AUTOSAR XML (schema 00050)
package /IBNvBlkSWC_1
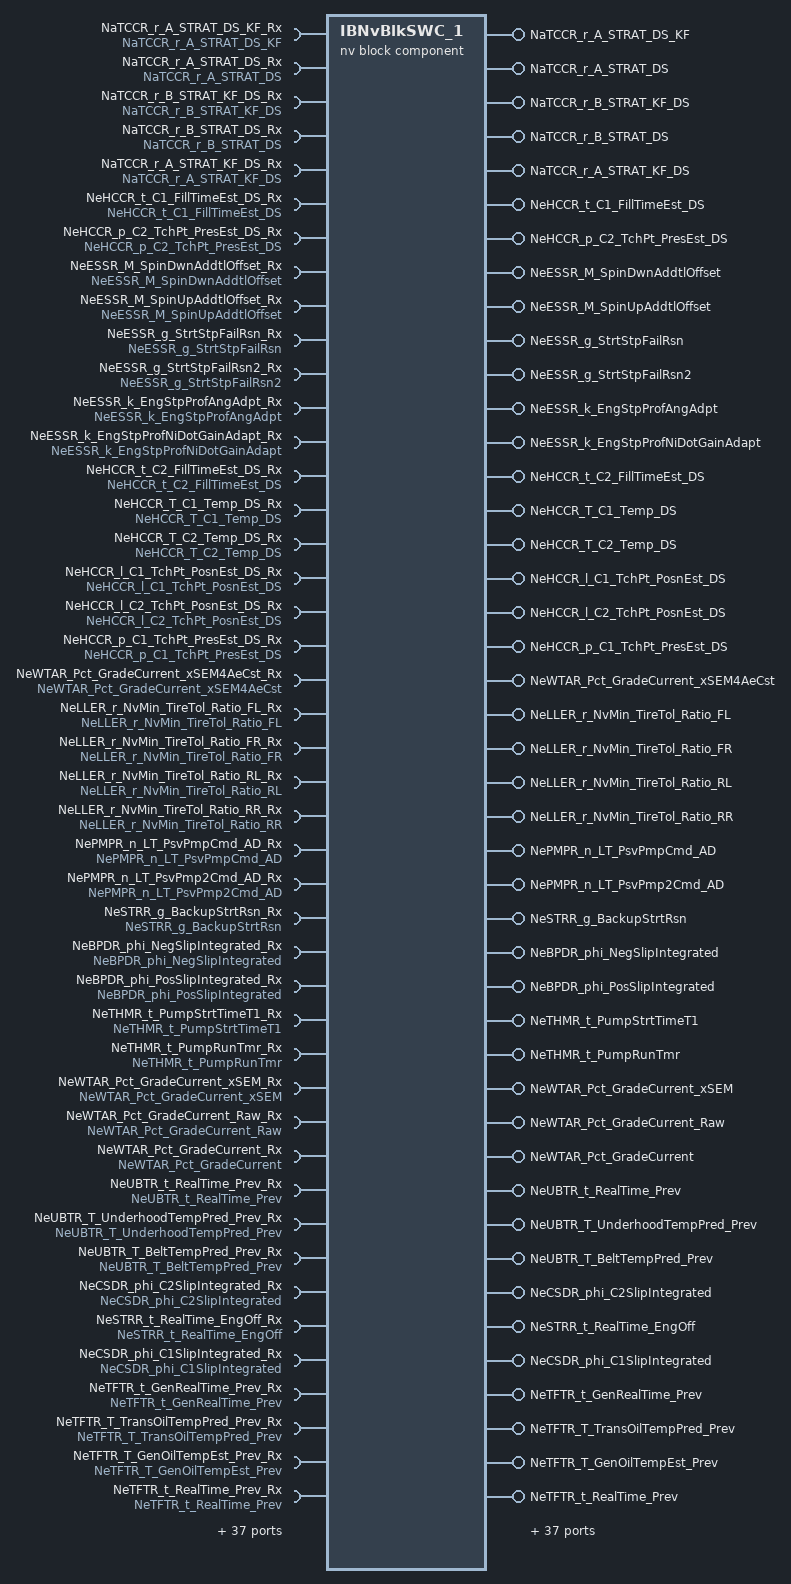
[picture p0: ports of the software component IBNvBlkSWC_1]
  nv block sw component type IBNvBlkSWC_1
    provide port NaTCCR_r_A_STRAT_DS_KF: nv-provide-com-spec{ram-block-init-value=ArrayValues:[ArrayElement0:0, ArrayElement1:0, ArrayElement2:0, ArrayElement3:0, ArrayElement4:0, ArrayElement5:0, ArrayElement6:0, ArrayElement7:0, ArrayElement8:0, ArrayElement9:0, ArrayElement10:0, ArrayElement11:0, ArrayElement12:0, ArrayElement13:0, ArrayElement14:0, ArrayElement15:0, ArrayElement16:0, ArrayElement17:0, ArrayElement18:0, ArrayElement19:0, ArrayElement20:0, ArrayElement21:0], rom-block-init-value=ArrayValues:[ArrayElement0:0, ArrayElement1:0, ArrayElement2:0, ArrayElement3:0, ArrayElement4:0, ArrayElement5:0, ArrayElement6:0, ArrayElement7:0, ArrayElement8:0, ArrayElement9:0, ArrayElement10:0, ArrayElement11:0, ArrayElement12:0, ArrayElement13:0, ArrayElement14:0, ArrayElement15:0, ArrayElement16:0, ArrayElement17:0, ArrayElement18:0, ArrayElement19:0, ArrayElement20:0, ArrayElement21:0], variable=NaTCCR_r_A_STRAT_DS_KF}, provided-interface=NaTCCR_r_A_STRAT_DS_KF
    require port NaTCCR_r_A_STRAT_DS_KF_Rx: nv-require-com-spec{init-value=ArrayValues:[ArrayElement0:0, ArrayElement1:0, ArrayElement2:0, ArrayElement3:0, ArrayElement4:0, ArrayElement5:0, ArrayElement6:0, ArrayElement7:0, ArrayElement8:0, ArrayElement9:0, ArrayElement10:0, ArrayElement11:0, ArrayElement12:0, ArrayElement13:0, ArrayElement14:0, ArrayElement15:0, ArrayElement16:0, ArrayElement17:0, ArrayElement18:0, ArrayElement19:0, ArrayElement20:0, ArrayElement21:0], variable=NaTCCR_r_A_STRAT_DS_KF}, required-interface=NaTCCR_r_A_STRAT_DS_KF
    provide port NaTCCR_r_A_STRAT_DS: nv-provide-com-spec{ram-block-init-value=ArrayValues:[ArrayElement0:0, ArrayElement1:0, ArrayElement2:0, ArrayElement3:0, ArrayElement4:0, ArrayElement5:0, ArrayElement6:0, ArrayElement7:0, ArrayElement8:0, ArrayElement9:0, ArrayElement10:0, ArrayElement11:0, ArrayElement12:0, ArrayElement13:0, ArrayElement14:0, ArrayElement15:0, ArrayElement16:0, ArrayElement17:0, ArrayElement18:0, ArrayElement19:0, ArrayElement20:0, ArrayElement21:0], rom-block-init-value=ArrayValues:[ArrayElement0:0, ArrayElement1:0, ArrayElement2:0, ArrayElement3:0, ArrayElement4:0, ArrayElement5:0, ArrayElement6:0, ArrayElement7:0, ArrayElement8:0, ArrayElement9:0, ArrayElement10:0, ArrayElement11:0, ArrayElement12:0, ArrayElement13:0, ArrayElement14:0, ArrayElement15:0, ArrayElement16:0, ArrayElement17:0, ArrayElement18:0, ArrayElement19:0, ArrayElement20:0, ArrayElement21:0], variable=NaTCCR_r_A_STRAT_DS}, provided-interface=NaTCCR_r_A_STRAT_DS
    require port NaTCCR_r_A_STRAT_DS_Rx: nv-require-com-spec{init-value=ArrayValues:[ArrayElement0:0, ArrayElement1:0, ArrayElement2:0, ArrayElement3:0, ArrayElement4:0, ArrayElement5:0, ArrayElement6:0, ArrayElement7:0, ArrayElement8:0, ArrayElement9:0, ArrayElement10:0, ArrayElement11:0, ArrayElement12:0, ArrayElement13:0, ArrayElement14:0, ArrayElement15:0, ArrayElement16:0, ArrayElement17:0, ArrayElement18:0, ArrayElement19:0, ArrayElement20:0, ArrayElement21:0], variable=NaTCCR_r_A_STRAT_DS}, required-interface=NaTCCR_r_A_STRAT_DS
    provide port NaTCCR_r_B_STRAT_KF_DS: nv-provide-com-spec{ram-block-init-value=ArrayValues:[ArrayElement0:0, ArrayElement1:0, ArrayElement2:0, ArrayElement3:0, ArrayElement4:0, ArrayElement5:0, ArrayElement6:0, ArrayElement7:0, ArrayElement8:0, ArrayElement9:0, ArrayElement10:0, ArrayElement11:0, ArrayElement12:0, ArrayElement13:0, ArrayElement14:0, ArrayElement15:0, ArrayElement16:0, ArrayElement17:0, ArrayElement18:0, ArrayElement19:0, ArrayElement20:0, ArrayElement21:0], rom-block-init-value=ArrayValues:[ArrayElement0:0, ArrayElement1:0, ArrayElement2:0, ArrayElement3:0, ArrayElement4:0, ArrayElement5:0, ArrayElement6:0, ArrayElement7:0, ArrayElement8:0, ArrayElement9:0, ArrayElement10:0, ArrayElement11:0, ArrayElement12:0, ArrayElement13:0, ArrayElement14:0, ArrayElement15:0, ArrayElement16:0, ArrayElement17:0, ArrayElement18:0, ArrayElement19:0, ArrayElement20:0, ArrayElement21:0], variable=NaTCCR_r_B_STRAT_KF_DS}, provided-interface=NaTCCR_r_B_STRAT_KF_DS
    require port NaTCCR_r_B_STRAT_KF_DS_Rx: nv-require-com-spec{init-value=ArrayValues:[ArrayElement0:0, ArrayElement1:0, ArrayElement2:0, ArrayElement3:0, ArrayElement4:0, ArrayElement5:0, ArrayElement6:0, ArrayElement7:0, ArrayElement8:0, ArrayElement9:0, ArrayElement10:0, ArrayElement11:0, ArrayElement12:0, ArrayElement13:0, ArrayElement14:0, ArrayElement15:0, ArrayElement16:0, ArrayElement17:0, ArrayElement18:0, ArrayElement19:0, ArrayElement20:0, ArrayElement21:0], variable=NaTCCR_r_B_STRAT_KF_DS}, required-interface=NaTCCR_r_B_STRAT_KF_DS
    provide port NaTCCR_r_B_STRAT_DS: nv-provide-com-spec{ram-block-init-value=ArrayValues:[ArrayElement0:0, ArrayElement1:0, ArrayElement2:0, ArrayElement3:0, ArrayElement4:0, ArrayElement5:0, ArrayElement6:0, ArrayElement7:0, ArrayElement8:0, ArrayElement9:0, ArrayElement10:0, ArrayElement11:0, ArrayElement12:0, ArrayElement13:0, ArrayElement14:0, ArrayElement15:0, ArrayElement16:0, ArrayElement17:0, ArrayElement18:0, ArrayElement19:0, ArrayElement20:0, ArrayElement21:0], rom-block-init-value=ArrayValues:[ArrayElement0:0, ArrayElement1:0, ArrayElement2:0, ArrayElement3:0, ArrayElement4:0, ArrayElement5:0, ArrayElement6:0, ArrayElement7:0, ArrayElement8:0, ArrayElement9:0, ArrayElement10:0, ArrayElement11:0, ArrayElement12:0, ArrayElement13:0, ArrayElement14:0, ArrayElement15:0, ArrayElement16:0, ArrayElement17:0, ArrayElement18:0, ArrayElement19:0, ArrayElement20:0, ArrayElement21:0], variable=NaTCCR_r_B_STRAT_DS}, provided-interface=NaTCCR_r_B_STRAT_DS
    require port NaTCCR_r_B_STRAT_DS_Rx: nv-require-com-spec{init-value=ArrayValues:[ArrayElement0:0, ArrayElement1:0, ArrayElement2:0, ArrayElement3:0, ArrayElement4:0, ArrayElement5:0, ArrayElement6:0, ArrayElement7:0, ArrayElement8:0, ArrayElement9:0, ArrayElement10:0, ArrayElement11:0, ArrayElement12:0, ArrayElement13:0, ArrayElement14:0, ArrayElement15:0, ArrayElement16:0, ArrayElement17:0, ArrayElement18:0, ArrayElement19:0, ArrayElement20:0, ArrayElement21:0], variable=NaTCCR_r_B_STRAT_DS}, required-interface=NaTCCR_r_B_STRAT_DS
    provide port NaTCCR_r_A_STRAT_KF_DS: nv-provide-com-spec{ram-block-init-value=ArrayValues:[ArrayElement0:0, ArrayElement1:0, ArrayElement2:0, ArrayElement3:0, ArrayElement4:0, ArrayElement5:0, ArrayElement6:0, ArrayElement7:0, ArrayElement8:0, ArrayElement9:0, ArrayElement10:0, ArrayElement11:0, ArrayElement12:0, ArrayElement13:0, ArrayElement14:0, ArrayElement15:0, ArrayElement16:0, ArrayElement17:0, ArrayElement18:0, ArrayElement19:0, ArrayElement20:0, ArrayElement21:0], rom-block-init-value=ArrayValues:[ArrayElement0:0, ArrayElement1:0, ArrayElement2:0, ArrayElement3:0, ArrayElement4:0, ArrayElement5:0, ArrayElement6:0, ArrayElement7:0, ArrayElement8:0, ArrayElement9:0, ArrayElement10:0, ArrayElement11:0, ArrayElement12:0, ArrayElement13:0, ArrayElement14:0, ArrayElement15:0, ArrayElement16:0, ArrayElement17:0, ArrayElement18:0, ArrayElement19:0, ArrayElement20:0, ArrayElement21:0], variable=NaTCCR_r_A_STRAT_KF_DS}, provided-interface=NaTCCR_r_A_STRAT_KF_DS
    require port NaTCCR_r_A_STRAT_KF_DS_Rx: nv-require-com-spec{init-value=ArrayValues:[ArrayElement0:0, ArrayElement1:0, ArrayElement2:0, ArrayElement3:0, ArrayElement4:0, ArrayElement5:0, ArrayElement6:0, ArrayElement7:0, ArrayElement8:0, ArrayElement9:0, ArrayElement10:0, ArrayElement11:0, ArrayElement12:0, ArrayElement13:0, ArrayElement14:0, ArrayElement15:0, ArrayElement16:0, ArrayElement17:0, ArrayElement18:0, ArrayElement19:0, ArrayElement20:0, ArrayElement21:0], variable=NaTCCR_r_A_STRAT_KF_DS}, required-interface=NaTCCR_r_A_STRAT_KF_DS
    provide port NeHCCR_t_C1_FillTimeEst_DS: nv-provide-com-spec{ram-block-init-value=Value:4294967295, rom-block-init-value=Value:4294967295, variable=NeHCCR_t_C1_FillTimeEst_DS}, provided-interface=NeHCCR_t_C1_FillTimeEst_DS
    require port NeHCCR_t_C1_FillTimeEst_DS_Rx: nv-require-com-spec{init-value=Value:4294967295, variable=NeHCCR_t_C1_FillTimeEst_DS}, required-interface=NeHCCR_t_C1_FillTimeEst_DS
    provide port NeHCCR_p_C2_TchPt_PresEst_DS: nv-provide-com-spec{ram-block-init-value=Value:4294967295, rom-block-init-value=Value:4294967295, variable=NeHCCR_p_C2_TchPt_PresEst_DS}, provided-interface=NeHCCR_p_C2_TchPt_PresEst_DS
    require port NeHCCR_p_C2_TchPt_PresEst_DS_Rx: nv-require-com-spec{init-value=Value:4294967295, variable=NeHCCR_p_C2_TchPt_PresEst_DS}, required-interface=NeHCCR_p_C2_TchPt_PresEst_DS
    provide port NeESSR_M_SpinDwnAddtlOffset: nv-provide-com-spec{ram-block-init-value=Value:0, rom-block-init-value=Value:0, variable=NeESSR_M_SpinDwnAddtlOffset}, provided-interface=NeESSR_M_SpinDwnAddtlOffset
    require port NeESSR_M_SpinDwnAddtlOffset_Rx: nv-require-com-spec{init-value=Value:0, variable=NeESSR_M_SpinDwnAddtlOffset}, required-interface=NeESSR_M_SpinDwnAddtlOffset
    provide port NeESSR_M_SpinUpAddtlOffset: nv-provide-com-spec{ram-block-init-value=Value:0, rom-block-init-value=Value:0, variable=NeESSR_M_SpinUpAddtlOffset}, provided-interface=NeESSR_M_SpinUpAddtlOffset
    require port NeESSR_M_SpinUpAddtlOffset_Rx: nv-require-com-spec{init-value=Value:0, variable=NeESSR_M_SpinUpAddtlOffset}, required-interface=NeESSR_M_SpinUpAddtlOffset
    provide port NeESSR_g_StrtStpFailRsn: nv-provide-com-spec{ram-block-init-value=Value:4294967295, rom-block-init-value=Value:4294967295, variable=NeESSR_g_StrtStpFailRsn}, provided-interface=NeESSR_g_StrtStpFailRsn
    require port NeESSR_g_StrtStpFailRsn_Rx: nv-require-com-spec{init-value=Value:4294967295, variable=NeESSR_g_StrtStpFailRsn}, required-interface=NeESSR_g_StrtStpFailRsn
    provide port NeESSR_g_StrtStpFailRsn2: nv-provide-com-spec{ram-block-init-value=Value:0, rom-block-init-value=Value:0, variable=NeESSR_g_StrtStpFailRsn2}, provided-interface=NeESSR_g_StrtStpFailRsn2
    require port NeESSR_g_StrtStpFailRsn2_Rx: nv-require-com-spec{init-value=Value:0, variable=NeESSR_g_StrtStpFailRsn2}, required-interface=NeESSR_g_StrtStpFailRsn2
    provide port NeESSR_k_EngStpProfAngAdpt: nv-provide-com-spec{ram-block-init-value=Value:0, rom-block-init-value=Value:0, variable=NeESSR_k_EngStpProfAngAdpt}, provided-interface=NeESSR_k_EngStpProfAngAdpt
    require port NeESSR_k_EngStpProfAngAdpt_Rx: nv-require-com-spec{init-value=Value:0, variable=NeESSR_k_EngStpProfAngAdpt}, required-interface=NeESSR_k_EngStpProfAngAdpt
    provide port NeESSR_k_EngStpProfNiDotGainAdapt: nv-provide-com-spec{ram-block-init-value=Value:0, rom-block-init-value=Value:0, variable=NeESSR_k_EngStpProfNiDotGainAdapt}, provided-interface=NeESSR_k_EngStpProfNiDotGainAdapt
    require port NeESSR_k_EngStpProfNiDotGainAdapt_Rx: nv-require-com-spec{init-value=Value:0, variable=NeESSR_k_EngStpProfNiDotGainAdapt}, required-interface=NeESSR_k_EngStpProfNiDotGainAdapt
    provide port NeHCCR_t_C2_FillTimeEst_DS: nv-provide-com-spec{ram-block-init-value=Value:4294967295, rom-block-init-value=Value:4294967295, variable=NeHCCR_t_C2_FillTimeEst_DS}, provided-interface=NeHCCR_t_C2_FillTimeEst_DS
    require port NeHCCR_t_C2_FillTimeEst_DS_Rx: nv-require-com-spec{init-value=Value:4294967295, variable=NeHCCR_t_C2_FillTimeEst_DS}, required-interface=NeHCCR_t_C2_FillTimeEst_DS
    provide port NeHCCR_T_C1_Temp_DS: nv-provide-com-spec{ram-block-init-value=Value:4294967295, rom-block-init-value=Value:4294967295, variable=NeHCCR_T_C1_Temp_DS}, provided-interface=NeHCCR_T_C1_Temp_DS
    require port NeHCCR_T_C1_Temp_DS_Rx: nv-require-com-spec{init-value=Value:4294967295, variable=NeHCCR_T_C1_Temp_DS}, required-interface=NeHCCR_T_C1_Temp_DS
    provide port NeHCCR_T_C2_Temp_DS: nv-provide-com-spec{ram-block-init-value=Value:4294967295, rom-block-init-value=Value:4294967295, variable=NeHCCR_T_C2_Temp_DS}, provided-interface=NeHCCR_T_C2_Temp_DS
    require port NeHCCR_T_C2_Temp_DS_Rx: nv-require-com-spec{init-value=Value:4294967295, variable=NeHCCR_T_C2_Temp_DS}, required-interface=NeHCCR_T_C2_Temp_DS
    provide port NeHCCR_l_C1_TchPt_PosnEst_DS: nv-provide-com-spec{ram-block-init-value=Value:4294967295, rom-block-init-value=Value:4294967295, variable=NeHCCR_l_C1_TchPt_PosnEst_DS}, provided-interface=NeHCCR_l_C1_TchPt_PosnEst_DS
    require port NeHCCR_l_C1_TchPt_PosnEst_DS_Rx: nv-require-com-spec{init-value=Value:4294967295, variable=NeHCCR_l_C1_TchPt_PosnEst_DS}, required-interface=NeHCCR_l_C1_TchPt_PosnEst_DS
    provide port NeHCCR_l_C2_TchPt_PosnEst_DS: nv-provide-com-spec{ram-block-init-value=Value:4294967295, rom-block-init-value=Value:4294967295, variable=NeHCCR_l_C2_TchPt_PosnEst_DS}, provided-interface=NeHCCR_l_C2_TchPt_PosnEst_DS
    require port NeHCCR_l_C2_TchPt_PosnEst_DS_Rx: nv-require-com-spec{init-value=Value:4294967295, variable=NeHCCR_l_C2_TchPt_PosnEst_DS}, required-interface=NeHCCR_l_C2_TchPt_PosnEst_DS
    provide port NeHCCR_p_C1_TchPt_PresEst_DS: nv-provide-com-spec{ram-block-init-value=Value:4294967295, rom-block-init-value=Value:4294967295, variable=NeHCCR_p_C1_TchPt_PresEst_DS}, provided-interface=NeHCCR_p_C1_TchPt_PresEst_DS
    require port NeHCCR_p_C1_TchPt_PresEst_DS_Rx: nv-require-com-spec{init-value=Value:4294967295, variable=NeHCCR_p_C1_TchPt_PresEst_DS}, required-interface=NeHCCR_p_C1_TchPt_PresEst_DS
    provide port NeWTAR_Pct_GradeCurrent_xSEM4AeCst: nv-provide-com-spec{ram-block-init-value=Value:0, rom-block-init-value=Value:0, variable=NeWTAR_Pct_GradeCurrent_xSEM4AeCst}, provided-interface=NeWTAR_Pct_GradeCurrent_xSEM4AeCst
    require port NeWTAR_Pct_GradeCurrent_xSEM4AeCst_Rx: nv-require-com-spec{init-value=Value:0, variable=NeWTAR_Pct_GradeCurrent_xSEM4AeCst}, required-interface=NeWTAR_Pct_GradeCurrent_xSEM4AeCst
    provide port NeLLER_r_NvMin_TireTol_Ratio_FL: nv-provide-com-spec{ram-block-init-value=Value:0, rom-block-init-value=Value:0, variable=NeLLER_r_NvMin_TireTol_Ratio_FL}, provided-interface=NeLLER_r_NvMin_TireTol_Ratio_FL
    require port NeLLER_r_NvMin_TireTol_Ratio_FL_Rx: nv-require-com-spec{init-value=Value:0, variable=NeLLER_r_NvMin_TireTol_Ratio_FL}, required-interface=NeLLER_r_NvMin_TireTol_Ratio_FL
    provide port NeLLER_r_NvMin_TireTol_Ratio_FR: nv-provide-com-spec{ram-block-init-value=Value:0, rom-block-init-value=Value:0, variable=NeLLER_r_NvMin_TireTol_Ratio_FR}, provided-interface=NeLLER_r_NvMin_TireTol_Ratio_FR
    require port NeLLER_r_NvMin_TireTol_Ratio_FR_Rx: nv-require-com-spec{init-value=Value:0, variable=NeLLER_r_NvMin_TireTol_Ratio_FR}, required-interface=NeLLER_r_NvMin_TireTol_Ratio_FR
    provide port NeLLER_r_NvMin_TireTol_Ratio_RL: nv-provide-com-spec{ram-block-init-value=Value:0, rom-block-init-value=Value:0, variable=NeLLER_r_NvMin_TireTol_Ratio_RL}, provided-interface=NeLLER_r_NvMin_TireTol_Ratio_RL
    require port NeLLER_r_NvMin_TireTol_Ratio_RL_Rx: nv-require-com-spec{init-value=Value:0, variable=NeLLER_r_NvMin_TireTol_Ratio_RL}, required-interface=NeLLER_r_NvMin_TireTol_Ratio_RL
    provide port NeLLER_r_NvMin_TireTol_Ratio_RR: nv-provide-com-spec{ram-block-init-value=Value:0, rom-block-init-value=Value:0, variable=NeLLER_r_NvMin_TireTol_Ratio_RR}, provided-interface=NeLLER_r_NvMin_TireTol_Ratio_RR
    require port NeLLER_r_NvMin_TireTol_Ratio_RR_Rx: nv-require-com-spec{init-value=Value:0, variable=NeLLER_r_NvMin_TireTol_Ratio_RR}, required-interface=NeLLER_r_NvMin_TireTol_Ratio_RR
    provide port NePMPR_n_LT_PsvPmpCmd_AD: nv-provide-com-spec{ram-block-init-value=Value:0, rom-block-init-value=Value:0, variable=NePMPR_n_LT_PsvPmpCmd_AD}, provided-interface=NePMPR_n_LT_PsvPmpCmd_AD
    require port NePMPR_n_LT_PsvPmpCmd_AD_Rx: nv-require-com-spec{init-value=Value:0, variable=NePMPR_n_LT_PsvPmpCmd_AD}, required-interface=NePMPR_n_LT_PsvPmpCmd_AD
    provide port NePMPR_n_LT_PsvPmp2Cmd_AD: nv-provide-com-spec{ram-block-init-value=Value:0, rom-block-init-value=Value:0, variable=NePMPR_n_LT_PsvPmp2Cmd_AD}, provided-interface=NePMPR_n_LT_PsvPmp2Cmd_AD
    require port NePMPR_n_LT_PsvPmp2Cmd_AD_Rx: nv-require-com-spec{init-value=Value:0, variable=NePMPR_n_LT_PsvPmp2Cmd_AD}, required-interface=NePMPR_n_LT_PsvPmp2Cmd_AD
    provide port NeSTRR_g_BackupStrtRsn: nv-provide-com-spec{ram-block-init-value=Value:0, rom-block-init-value=Value:0, variable=NeSTRR_g_BackupStrtRsn}, provided-interface=NeSTRR_g_BackupStrtRsn
    require port NeSTRR_g_BackupStrtRsn_Rx: nv-require-com-spec{init-value=Value:0, variable=NeSTRR_g_BackupStrtRsn}, required-interface=NeSTRR_g_BackupStrtRsn
    provide port NeBPDR_phi_NegSlipIntegrated: nv-provide-com-spec{ram-block-init-value=Value:0, rom-block-init-value=Value:0, variable=NeBPDR_phi_NegSlipIntegrated}, provided-interface=NeBPDR_phi_NegSlipIntegrated
    require port NeBPDR_phi_NegSlipIntegrated_Rx: nv-require-com-spec{init-value=Value:0, variable=NeBPDR_phi_NegSlipIntegrated}, required-interface=NeBPDR_phi_NegSlipIntegrated
    provide port NeBPDR_phi_PosSlipIntegrated: nv-provide-com-spec{ram-block-init-value=Value:0, rom-block-init-value=Value:0, variable=NeBPDR_phi_PosSlipIntegrated}, provided-interface=NeBPDR_phi_PosSlipIntegrated
    require port NeBPDR_phi_PosSlipIntegrated_Rx: nv-require-com-spec{init-value=Value:0, variable=NeBPDR_phi_PosSlipIntegrated}, required-interface=NeBPDR_phi_PosSlipIntegrated
    provide port NeTHMR_t_PumpStrtTimeT1: nv-provide-com-spec{ram-block-init-value=Value:0, rom-block-init-value=Value:0, variable=NeTHMR_t_PumpStrtTimeT1}, provided-interface=NeTHMR_t_PumpStrtTimeT1
    require port NeTHMR_t_PumpStrtTimeT1_Rx: nv-require-com-spec{init-value=Value:0, variable=NeTHMR_t_PumpStrtTimeT1}, required-interface=NeTHMR_t_PumpStrtTimeT1
    provide port NeTHMR_t_PumpRunTmr: nv-provide-com-spec{ram-block-init-value=Value:0, rom-block-init-value=Value:0, variable=NeTHMR_t_PumpRunTmr}, provided-interface=NeTHMR_t_PumpRunTmr
    require port NeTHMR_t_PumpRunTmr_Rx: nv-require-com-spec{init-value=Value:0, variable=NeTHMR_t_PumpRunTmr}, required-interface=NeTHMR_t_PumpRunTmr
    provide port NeWTAR_Pct_GradeCurrent_xSEM: nv-provide-com-spec{ram-block-init-value=Value:0, rom-block-init-value=Value:0, variable=NeWTAR_Pct_GradeCurrent_xSEM}, provided-interface=NeWTAR_Pct_GradeCurrent_xSEM
    require port NeWTAR_Pct_GradeCurrent_xSEM_Rx: nv-require-com-spec{init-value=Value:0, variable=NeWTAR_Pct_GradeCurrent_xSEM}, required-interface=NeWTAR_Pct_GradeCurrent_xSEM
    provide port NeWTAR_Pct_GradeCurrent_Raw: nv-provide-com-spec{ram-block-init-value=Value:0, rom-block-init-value=Value:0, variable=NeWTAR_Pct_GradeCurrent_Raw}, provided-interface=NeWTAR_Pct_GradeCurrent_Raw
    require port NeWTAR_Pct_GradeCurrent_Raw_Rx: nv-require-com-spec{init-value=Value:0, variable=NeWTAR_Pct_GradeCurrent_Raw}, required-interface=NeWTAR_Pct_GradeCurrent_Raw
    provide port NeWTAR_Pct_GradeCurrent: nv-provide-com-spec{ram-block-init-value=Value:0, rom-block-init-value=Value:0, variable=NeWTAR_Pct_GradeCurrent}, provided-interface=NeWTAR_Pct_GradeCurrent
    require port NeWTAR_Pct_GradeCurrent_Rx: nv-require-com-spec{init-value=Value:0, variable=NeWTAR_Pct_GradeCurrent}, required-interface=NeWTAR_Pct_GradeCurrent
    provide port NeUBTR_t_RealTime_Prev: nv-provide-com-spec{ram-block-init-value=Value:0, rom-block-init-value=Value:0, variable=NeUBTR_t_RealTime_Prev}, provided-interface=NeUBTR_t_RealTime_Prev
    require port NeUBTR_t_RealTime_Prev_Rx: nv-require-com-spec{init-value=Value:0, variable=NeUBTR_t_RealTime_Prev}, required-interface=NeUBTR_t_RealTime_Prev
    provide port NeUBTR_T_UnderhoodTempPred_Prev: nv-provide-com-spec{ram-block-init-value=Value:0, rom-block-init-value=Value:0, variable=NeUBTR_T_UnderhoodTempPred_Prev}, provided-interface=NeUBTR_T_UnderhoodTempPred_Prev
    require port NeUBTR_T_UnderhoodTempPred_Prev_Rx: nv-require-com-spec{init-value=Value:0, variable=NeUBTR_T_UnderhoodTempPred_Prev}, required-interface=NeUBTR_T_UnderhoodTempPred_Prev
    provide port NeUBTR_T_BeltTempPred_Prev: nv-provide-com-spec{ram-block-init-value=Value:0, rom-block-init-value=Value:0, variable=NeUBTR_T_BeltTempPred_Prev}, provided-interface=NeUBTR_T_BeltTempPred_Prev
    require port NeUBTR_T_BeltTempPred_Prev_Rx: nv-require-com-spec{init-value=Value:0, variable=NeUBTR_T_BeltTempPred_Prev}, required-interface=NeUBTR_T_BeltTempPred_Prev
    provide port NeCSDR_phi_C2SlipIntegrated: nv-provide-com-spec{ram-block-init-value=Value:0, rom-block-init-value=Value:0, variable=NeCSDR_phi_C2SlipIntegrated}, provided-interface=NeCSDR_phi_C2SlipIntegrated
    require port NeCSDR_phi_C2SlipIntegrated_Rx: nv-require-com-spec{init-value=Value:0, variable=NeCSDR_phi_C2SlipIntegrated}, required-interface=NeCSDR_phi_C2SlipIntegrated
    provide port NeSTRR_t_RealTime_EngOff: nv-provide-com-spec{ram-block-init-value=Value:0, rom-block-init-value=Value:0, variable=NeSTRR_t_RealTime_EngOff}, provided-interface=NeSTRR_t_RealTime_EngOff
    require port NeSTRR_t_RealTime_EngOff_Rx: nv-require-com-spec{init-value=Value:0, variable=NeSTRR_t_RealTime_EngOff}, required-interface=NeSTRR_t_RealTime_EngOff
    provide port NeCSDR_phi_C1SlipIntegrated: nv-provide-com-spec{ram-block-init-value=Value:0, rom-block-init-value=Value:0, variable=NeCSDR_phi_C1SlipIntegrated}, provided-interface=NeCSDR_phi_C1SlipIntegrated
    require port NeCSDR_phi_C1SlipIntegrated_Rx: nv-require-com-spec{init-value=Value:0, variable=NeCSDR_phi_C1SlipIntegrated}, required-interface=NeCSDR_phi_C1SlipIntegrated
    provide port NeTFTR_t_GenRealTime_Prev: nv-provide-com-spec{ram-block-init-value=Value:0, rom-block-init-value=Value:0, variable=NeTFTR_t_GenRealTime_Prev}, provided-interface=NeTFTR_t_GenRealTime_Prev
    require port NeTFTR_t_GenRealTime_Prev_Rx: nv-require-com-spec{init-value=Value:0, variable=NeTFTR_t_GenRealTime_Prev}, required-interface=NeTFTR_t_GenRealTime_Prev
    provide port NeTFTR_T_TransOilTempPred_Prev: nv-provide-com-spec{ram-block-init-value=Value:0, rom-block-init-value=Value:0, variable=NeTFTR_T_TransOilTempPred_Prev}, provided-interface=NeTFTR_T_TransOilTempPred_Prev
    require port NeTFTR_T_TransOilTempPred_Prev_Rx: nv-require-com-spec{init-value=Value:0, variable=NeTFTR_T_TransOilTempPred_Prev}, required-interface=NeTFTR_T_TransOilTempPred_Prev
    provide port NeTFTR_T_GenOilTempEst_Prev: nv-provide-com-spec{ram-block-init-value=Value:0, rom-block-init-value=Value:0, variable=NeTFTR_T_GenOilTempEst_Prev}, provided-interface=NeTFTR_T_GenOilTempEst_Prev
    require port NeTFTR_T_GenOilTempEst_Prev_Rx: nv-require-com-spec{init-value=Value:0, variable=NeTFTR_T_GenOilTempEst_Prev}, required-interface=NeTFTR_T_GenOilTempEst_Prev
    provide port NeTFTR_t_RealTime_Prev: nv-provide-com-spec{ram-block-init-value=Value:0, rom-block-init-value=Value:0, variable=NeTFTR_t_RealTime_Prev}, provided-interface=NeTFTR_t_RealTime_Prev
    require port NeTFTR_t_RealTime_Prev_Rx: nv-require-com-spec{init-value=Value:0, variable=NeTFTR_t_RealTime_Prev}, required-interface=NeTFTR_t_RealTime_Prev
    provide port NeSTRR_g_ImmedStopRsn: nv-provide-com-spec{ram-block-init-value=Value:4294967295, rom-block-init-value=Value:4294967295, variable=NeSTRR_g_ImmedStopRsn}, provided-interface=NeSTRR_g_ImmedStopRsn
    require port NeSTRR_g_ImmedStopRsn_Rx: nv-require-com-spec{init-value=Value:4294967295, variable=NeSTRR_g_ImmedStopRsn}, required-interface=NeSTRR_g_ImmedStopRsn
    provide port NeSTRR_g_BumpStrtRsn: nv-provide-com-spec{ram-block-init-value=Value:0, rom-block-init-value=Value:0, variable=NeSTRR_g_BumpStrtRsn}, provided-interface=NeSTRR_g_BumpStrtRsn
    require port NeSTRR_g_BumpStrtRsn_Rx: nv-require-com-spec{init-value=Value:0, variable=NeSTRR_g_BumpStrtRsn}, required-interface=NeSTRR_g_BumpStrtRsn
    provide port NeRCVR_Cnt_LTR_CntrlrShtDwn_Cycles: nv-provide-com-spec{ram-block-init-value=Value:0, rom-block-init-value=Value:0, variable=NeRCVR_Cnt_LTR_CntrlrShtDwn_Cycles}, provided-interface=NeRCVR_Cnt_LTR_CntrlrShtDwn_Cycles
    require port NeRCVR_Cnt_LTR_CntrlrShtDwn_Cycles_Rx: nv-require-com-spec{init-value=Value:0, variable=NeRCVR_Cnt_LTR_CntrlrShtDwn_Cycles}, required-interface=NeRCVR_Cnt_LTR_CntrlrShtDwn_Cycles
    provide port NeRCVR_Cnt_HtrCore_CntrlrShtDwn_Cycles: nv-provide-com-spec{ram-block-init-value=Value:0, rom-block-init-value=Value:0, variable=NeRCVR_Cnt_HtrCore_CntrlrShtDwn_Cycles}, provided-interface=NeRCVR_Cnt_HtrCore_CntrlrShtDwn_Cycles
    require port NeRCVR_Cnt_HtrCore_CntrlrShtDwn_Cycles_Rx: nv-require-com-spec{init-value=Value:0, variable=NeRCVR_Cnt_HtrCore_CntrlrShtDwn_Cycles}, required-interface=NeRCVR_Cnt_HtrCore_CntrlrShtDwn_Cycles
    provide port NeRCVR_Cnt_HTL_CntrlrShtDwn_Cycles: nv-provide-com-spec{ram-block-init-value=Value:0, rom-block-init-value=Value:0, variable=NeRCVR_Cnt_HTL_CntrlrShtDwn_Cycles}, provided-interface=NeRCVR_Cnt_HTL_CntrlrShtDwn_Cycles
    require port NeRCVR_Cnt_HTL_CntrlrShtDwn_Cycles_Rx: nv-require-com-spec{init-value=Value:0, variable=NeRCVR_Cnt_HTL_CntrlrShtDwn_Cycles}, required-interface=NeRCVR_Cnt_HTL_CntrlrShtDwn_Cycles
    provide port NeRCVR_Cnt_CPV_CntrlrShtDwn_Cycles: nv-provide-com-spec{ram-block-init-value=Value:0, rom-block-init-value=Value:0, variable=NeRCVR_Cnt_CPV_CntrlrShtDwn_Cycles}, provided-interface=NeRCVR_Cnt_CPV_CntrlrShtDwn_Cycles
    require port NeRCVR_Cnt_CPV_CntrlrShtDwn_Cycles_Rx: nv-require-com-spec{init-value=Value:0, variable=NeRCVR_Cnt_CPV_CntrlrShtDwn_Cycles}, required-interface=NeRCVR_Cnt_CPV_CntrlrShtDwn_Cycles
    provide port NeHCCR_Cnt_C2CShifts_TchPtLrn: nv-provide-com-spec{ram-block-init-value=Value:65535, rom-block-init-value=Value:65535, variable=NeHCCR_Cnt_C2CShifts_TchPtLrn}, provided-interface=NeHCCR_Cnt_C2CShifts_TchPtLrn
    require port NeHCCR_Cnt_C2CShifts_TchPtLrn_Rx: nv-require-com-spec{init-value=Value:65535, variable=NeHCCR_Cnt_C2CShifts_TchPtLrn}, required-interface=NeHCCR_Cnt_C2CShifts_TchPtLrn
    provide port NeHCCR_Cnt_AllC2CShifts: nv-provide-com-spec{ram-block-init-value=Value:65535, rom-block-init-value=Value:65535, variable=NeHCCR_Cnt_AllC2CShifts}, provided-interface=NeHCCR_Cnt_AllC2CShifts
    require port NeHCCR_Cnt_AllC2CShifts_Rx: nv-require-com-spec{init-value=Value:65535, variable=NeHCCR_Cnt_AllC2CShifts}, required-interface=NeHCCR_Cnt_AllC2CShifts
    provide port NeESSR_Cnt_AdptInitValue: nv-provide-com-spec{ram-block-init-value=Value:0, rom-block-init-value=Value:0, variable=NeESSR_Cnt_AdptInitValue}, provided-interface=NeESSR_Cnt_AdptInitValue
    require port NeESSR_Cnt_AdptInitValue_Rx: nv-require-com-spec{init-value=Value:0, variable=NeESSR_Cnt_AdptInitValue}, required-interface=NeESSR_Cnt_AdptInitValue
    provide port NeBPDR_Cnt_BeltSlip_MFOP: nv-provide-com-spec{ram-block-init-value=Value:0, rom-block-init-value=Value:0, variable=NeBPDR_Cnt_BeltSlip_MFOP}, provided-interface=NeBPDR_Cnt_BeltSlip_MFOP
    require port NeBPDR_Cnt_BeltSlip_MFOP_Rx: nv-require-com-spec{init-value=Value:0, variable=NeBPDR_Cnt_BeltSlip_MFOP}, required-interface=NeBPDR_Cnt_BeltSlip_MFOP
    provide port NeBPSD_Cnt_BrkPdlLvlOneCktHi_MFOP: nv-provide-com-spec{ram-block-init-value=Value:0, rom-block-init-value=Value:0, variable=NeBPSD_Cnt_BrkPdlLvlOneCktHi_MFOP}, provided-interface=NeBPSD_Cnt_BrkPdlLvlOneCktHi_MFOP
    require port NeBPSD_Cnt_BrkPdlLvlOneCktHi_MFOP_Rx: nv-require-com-spec{init-value=Value:0, variable=NeBPSD_Cnt_BrkPdlLvlOneCktHi_MFOP}, required-interface=NeBPSD_Cnt_BrkPdlLvlOneCktHi_MFOP
    provide port NeBPSD_Cnt_BrkPdlLvlOneCktLo_MFOP: nv-provide-com-spec{ram-block-init-value=Value:0, rom-block-init-value=Value:0, variable=NeBPSD_Cnt_BrkPdlLvlOneCktLo_MFOP}, provided-interface=NeBPSD_Cnt_BrkPdlLvlOneCktLo_MFOP
    require port NeBPSD_Cnt_BrkPdlLvlOneCktLo_MFOP_Rx: nv-require-com-spec{init-value=Value:0, variable=NeBPSD_Cnt_BrkPdlLvlOneCktLo_MFOP}, required-interface=NeBPSD_Cnt_BrkPdlLvlOneCktLo_MFOP
    provide port NeBPSD_Cnt_BrkPdlSnsPerf_MFOP: nv-provide-com-spec{ram-block-init-value=Value:0, rom-block-init-value=Value:0, variable=NeBPSD_Cnt_BrkPdlSnsPerf_MFOP}, provided-interface=NeBPSD_Cnt_BrkPdlSnsPerf_MFOP
    require port NeBPSD_Cnt_BrkPdlSnsPerf_MFOP_Rx: nv-require-com-spec{init-value=Value:0, variable=NeBPSD_Cnt_BrkPdlSnsPerf_MFOP}, required-interface=NeBPSD_Cnt_BrkPdlSnsPerf_MFOP
    provide port NeTCCR_b_UpdLaw_DS: nv-provide-com-spec{ram-block-init-value=Value:0, rom-block-init-value=Value:0, variable=NeTCCR_b_UpdLaw_DS}, provided-interface=NeTCCR_b_UpdLaw_DS
    require port NeTCCR_b_UpdLaw_DS_Rx: nv-require-com-spec{init-value=Value:0, variable=NeTCCR_b_UpdLaw_DS}, required-interface=NeTCCR_b_UpdLaw_DS
    provide port NeSTFR_b_FailedStrtPrevCycle: nv-provide-com-spec{ram-block-init-value=Value:0, rom-block-init-value=Value:0, variable=NeSTFR_b_FailedStrtPrevCycle}, provided-interface=NeSTFR_b_FailedStrtPrevCycle
    require port NeSTFR_b_FailedStrtPrevCycle_Rx: nv-require-com-spec{init-value=Value:0, variable=NeSTFR_b_FailedStrtPrevCycle}, required-interface=NeSTFR_b_FailedStrtPrevCycle
    provide port NeSTRR_b_RealTime_EngOFF_FA: nv-provide-com-spec{ram-block-init-value=Value:0, rom-block-init-value=Value:0, variable=NeSTRR_b_RealTime_EngOFF_FA}, provided-interface=NeSTRR_b_RealTime_EngOFF_FA
    require port NeSTRR_b_RealTime_EngOFF_FA_Rx: nv-require-com-spec{init-value=Value:0, variable=NeSTRR_b_RealTime_EngOFF_FA}, required-interface=NeSTRR_b_RealTime_EngOFF_FA
    provide port NeSTRR_b_StrtFailLowPwrLtch: nv-provide-com-spec{ram-block-init-value=Value:0, rom-block-init-value=Value:0, variable=NeSTRR_b_StrtFailLowPwrLtch}, provided-interface=NeSTRR_b_StrtFailLowPwrLtch
    require port NeSTRR_b_StrtFailLowPwrLtch_Rx: nv-require-com-spec{init-value=Value:0, variable=NeSTRR_b_StrtFailLowPwrLtch}, required-interface=NeSTRR_b_StrtFailLowPwrLtch
    provide port NePMPR_e_LTPsvPump_PstRnSt: nv-provide-com-spec{ram-block-init-value=Value:0, rom-block-init-value=Value:0, variable=NePMPR_e_LTPsvPump_PstRnSt}, provided-interface=NePMPR_e_LTPsvPump_PstRnSt
    require port NePMPR_e_LTPsvPump_PstRnSt_Rx: nv-require-com-spec{init-value=Value:0, variable=NePMPR_e_LTPsvPump_PstRnSt}, required-interface=NePMPR_e_LTPsvPump_PstRnSt
    provide port NePMPR_e_LTPsvPump2_PstRnSt: nv-provide-com-spec{ram-block-init-value=Value:0, rom-block-init-value=Value:0, variable=NePMPR_e_LTPsvPump2_PstRnSt}, provided-interface=NePMPR_e_LTPsvPump2_PstRnSt
    require port NePMPR_e_LTPsvPump2_PstRnSt_Rx: nv-require-com-spec{init-value=Value:0, variable=NePMPR_e_LTPsvPump2_PstRnSt}, required-interface=NePMPR_e_LTPsvPump2_PstRnSt
    provide port NePMPR_e_LT_PsvPmp2_PostRunCmd_AD: nv-provide-com-spec{ram-block-init-value=Value:0, rom-block-init-value=Value:0, variable=NePMPR_e_LT_PsvPmp2_PostRunCmd_AD}, provided-interface=NePMPR_e_LT_PsvPmp2_PostRunCmd_AD
    require port NePMPR_e_LT_PsvPmp2_PostRunCmd_AD_Rx: nv-require-com-spec{init-value=Value:0, variable=NePMPR_e_LT_PsvPmp2_PostRunCmd_AD}, required-interface=NePMPR_e_LT_PsvPmp2_PostRunCmd_AD
    provide port NeTMIR_e_HCP_LTP_FanAftRun_Rq: nv-provide-com-spec{ram-block-init-value=Value:0, rom-block-init-value=Value:0, variable=NeTMIR_e_HCP_LTP_FanAftRun_Rq}, provided-interface=NeTMIR_e_HCP_LTP_FanAftRun_Rq
    require port NeTMIR_e_HCP_LTP_FanAftRun_Rq_Rx: nv-require-com-spec{init-value=Value:0, variable=NeTMIR_e_HCP_LTP_FanAftRun_Rq}, required-interface=NeTMIR_e_HCP_LTP_FanAftRun_Rq
    provide port NePMPR_e_LT_PsvPmp_PostRunCmd_AD: nv-provide-com-spec{ram-block-init-value=Value:0, rom-block-init-value=Value:0, variable=NePMPR_e_LT_PsvPmp_PostRunCmd_AD}, provided-interface=NePMPR_e_LT_PsvPmp_PostRunCmd_AD
    require port NePMPR_e_LT_PsvPmp_PostRunCmd_AD_Rx: nv-require-com-spec{init-value=Value:0, variable=NePMPR_e_LT_PsvPmp_PostRunCmd_AD}, required-interface=NePMPR_e_LT_PsvPmp_PostRunCmd_AD
    provide port NeHCCR_b_C2TchPt_DtctFlg_DS: nv-provide-com-spec{ram-block-init-value=Value:1, rom-block-init-value=Value:1, variable=NeHCCR_b_C2TchPt_DtctFlg_DS}, provided-interface=NeHCCR_b_C2TchPt_DtctFlg_DS
    require port NeHCCR_b_C2TchPt_DtctFlg_DS_Rx: nv-require-com-spec{init-value=Value:1, variable=NeHCCR_b_C2TchPt_DtctFlg_DS}, required-interface=NeHCCR_b_C2TchPt_DtctFlg_DS
    provide port NeHCCR_b_C1TchPt_DtctFlg_DS: nv-provide-com-spec{ram-block-init-value=Value:1, rom-block-init-value=Value:1, variable=NeHCCR_b_C1TchPt_DtctFlg_DS}, provided-interface=NeHCCR_b_C1TchPt_DtctFlg_DS
    require port NeHCCR_b_C1TchPt_DtctFlg_DS_Rx: nv-require-com-spec{init-value=Value:1, variable=NeHCCR_b_C1TchPt_DtctFlg_DS}, required-interface=NeHCCR_b_C1TchPt_DtctFlg_DS
    provide port EeRCVR_U_HT_CabVlvSts_Min: nv-provide-com-spec{ram-block-init-value=Value:0, rom-block-init-value=Value:0, variable=EeRCVR_U_HT_CabVlvSts_Min}, provided-interface=EeRCVR_U_HT_CabVlvSts_Min
    require port EeRCVR_U_HT_CabVlvSts_Min_Rx: nv-require-com-spec{init-value=Value:0, variable=EeRCVR_U_HT_CabVlvSts_Min}, required-interface=EeRCVR_U_HT_CabVlvSts_Min
    provide port EeRCVR_U_HT_CabVlvSts_Max: nv-provide-com-spec{ram-block-init-value=Value:0, rom-block-init-value=Value:0, variable=EeRCVR_U_HT_CabVlvSts_Max}, provided-interface=EeRCVR_U_HT_CabVlvSts_Max
    require port EeRCVR_U_HT_CabVlvSts_Max_Rx: nv-require-com-spec{init-value=Value:0, variable=EeRCVR_U_HT_CabVlvSts_Max}, required-interface=EeRCVR_U_HT_CabVlvSts_Max
    provide port EeBPSR_U_LrndBrkPdlRestPos: nv-provide-com-spec{ram-block-init-value=Value:0, rom-block-init-value=Value:0, variable=EeBPSR_U_LrndBrkPdlRestPos}, provided-interface=EeBPSR_U_LrndBrkPdlRestPos
    require port EeBPSR_U_LrndBrkPdlRestPos_Rx: nv-require-com-spec{init-value=Value:0, variable=EeBPSR_U_LrndBrkPdlRestPos}, required-interface=EeBPSR_U_LrndBrkPdlRestPos
    provide port EeRCVR_Cnt_HTCV_Endstophits: nv-provide-com-spec{ram-block-init-value=Value:0, rom-block-init-value=Value:0, variable=EeRCVR_Cnt_HTCV_Endstophits}, provided-interface=EeRCVR_Cnt_HTCV_Endstophits
    require port EeRCVR_Cnt_HTCV_Endstophits_Rx: nv-require-com-spec{init-value=Value:0, variable=EeRCVR_Cnt_HTCV_Endstophits}, required-interface=EeRCVR_Cnt_HTCV_Endstophits
    provide port EeRCVR_e_HTCV_Calibration_Sts: nv-provide-com-spec{ram-block-init-value=Value:255, rom-block-init-value=Value:255, variable=EeRCVR_e_HTCV_Calibration_Sts}, provided-interface=EeRCVR_e_HTCV_Calibration_Sts
    require port EeRCVR_e_HTCV_Calibration_Sts_Rx: nv-require-com-spec{init-value=Value:255, variable=EeRCVR_e_HTCV_Calibration_Sts}, required-interface=EeRCVR_e_HTCV_Calibration_Sts
    provide port EeRCVR_Cnt_OEXV_CyclesSncCal: nv-provide-com-spec{ram-block-init-value=Value:0, rom-block-init-value=Value:0, variable=EeRCVR_Cnt_OEXV_CyclesSncCal}, provided-interface=EeRCVR_Cnt_OEXV_CyclesSncCal
    require port EeRCVR_Cnt_OEXV_CyclesSncCal_Rx: nv-require-com-spec{init-value=Value:0, variable=EeRCVR_Cnt_OEXV_CyclesSncCal}, required-interface=EeRCVR_Cnt_OEXV_CyclesSncCal
    provide port EeRCVR_Cnt_EXV_CyclesSncCal: nv-provide-com-spec{ram-block-init-value=Value:0, rom-block-init-value=Value:0, variable=EeRCVR_Cnt_EXV_CyclesSncCal}, provided-interface=EeRCVR_Cnt_EXV_CyclesSncCal
    require port EeRCVR_Cnt_EXV_CyclesSncCal_Rx: nv-require-com-spec{init-value=Value:0, variable=EeRCVR_Cnt_EXV_CyclesSncCal}, required-interface=EeRCVR_Cnt_EXV_CyclesSncCal
    provide port EeRCVR_Cnt_EEXV_CyclesSncCal: nv-provide-com-spec{ram-block-init-value=Value:0, rom-block-init-value=Value:0, variable=EeRCVR_Cnt_EEXV_CyclesSncCal}, provided-interface=EeRCVR_Cnt_EEXV_CyclesSncCal
    require port EeRCVR_Cnt_EEXV_CyclesSncCal_Rx: nv-require-com-spec{init-value=Value:0, variable=EeRCVR_Cnt_EEXV_CyclesSncCal}, required-interface=EeRCVR_Cnt_EEXV_CyclesSncCal
    provide port EeHTRR_Cnt_Htr_Unlck_RstSts: nv-provide-com-spec{ram-block-init-value=Value:0, rom-block-init-value=Value:0, variable=EeHTRR_Cnt_Htr_Unlck_RstSts}, provided-interface=EeHTRR_Cnt_Htr_Unlck_RstSts
    require port EeHTRR_Cnt_Htr_Unlck_RstSts_Rx: nv-require-com-spec{init-value=Value:0, variable=EeHTRR_Cnt_Htr_Unlck_RstSts}, required-interface=EeHTRR_Cnt_Htr_Unlck_RstSts
    provide port EeFSCR_b_HoodAjar_FanOff: nv-provide-com-spec{ram-block-init-value=Value:0, rom-block-init-value=Value:0, variable=EeFSCR_b_HoodAjar_FanOff}, provided-interface=EeFSCR_b_HoodAjar_FanOff
    require port EeFSCR_b_HoodAjar_FanOff_Rx: nv-require-com-spec{init-value=Value:0, variable=EeFSCR_b_HoodAjar_FanOff}, required-interface=EeFSCR_b_HoodAjar_FanOff
    provide port EeHTRR_Cnt_Htr_UnlockCntr: nv-provide-com-spec{ram-block-init-value=Value:0, rom-block-init-value=Value:0, variable=EeHTRR_Cnt_Htr_UnlockCntr}, provided-interface=EeHTRR_Cnt_Htr_UnlockCntr
    require port EeHTRR_Cnt_Htr_UnlockCntr_Rx: nv-require-com-spec{init-value=Value:0, variable=EeHTRR_Cnt_Htr_UnlockCntr}, required-interface=EeHTRR_Cnt_Htr_UnlockCntr
    provide port BeFSCR_b_RadFanTst_NotCmplte: nv-provide-com-spec{ram-block-init-value=Value:1, rom-block-init-value=Value:1, variable=BeFSCR_b_RadFanTst_NotCmplte}, provided-interface=BeFSCR_b_RadFanTst_NotCmplte
    require port BeFSCR_b_RadFanTst_NotCmplte_Rx: nv-require-com-spec{init-value=Value:1, variable=BeFSCR_b_RadFanTst_NotCmplte}, required-interface=BeFSCR_b_RadFanTst_NotCmplte
    provide port BeFSCR_b_RadFanTst_Failed: nv-provide-com-spec{ram-block-init-value=Value:1, rom-block-init-value=Value:1, variable=BeFSCR_b_RadFanTst_Failed}, provided-interface=BeFSCR_b_RadFanTst_Failed
    require port BeFSCR_b_RadFanTst_Failed_Rx: nv-require-com-spec{init-value=Value:1, variable=BeFSCR_b_RadFanTst_Failed}, required-interface=BeFSCR_b_RadFanTst_Failed
    behavior IB_NvBlkSWC_1: data-type-mapping=NVM_DataMappingSet, handle-termination-and-restart=NO-SUPPORT
    nv block descriptor ExpendableNonVolatile_Descr_Core1: support-dirty-flag=true
      nv-block-data-mappings:
        {nv-ram-block-element=autosar-variable-in-impl-datatype={root-variable-data-prototype=ExpendableNonVolatile_RamBlock_Core1, target-data-prototype=ExpendableNonVolatile_Ram_Core1/NaTCCR_r_A_STRAT_DS_KF}, read-nv-data=NaTCCR_r_A_STRAT_DS_KF.NaTCCR_r_A_STRAT_DS_KF}
        {nv-ram-block-element=autosar-variable-in-impl-datatype={root-variable-data-prototype=ExpendableNonVolatile_RamBlock_Core1, target-data-prototype=ExpendableNonVolatile_Ram_Core1/NaTCCR_r_A_STRAT_DS_KF}, written-nv-data=NaTCCR_r_A_STRAT_DS_KF_Rx.NaTCCR_r_A_STRAT_DS_KF}
        {nv-ram-block-element=autosar-variable-in-impl-datatype={root-variable-data-prototype=ExpendableNonVolatile_RamBlock_Core1, target-data-prototype=ExpendableNonVolatile_Ram_Core1/NaTCCR_r_A_STRAT_DS}, read-nv-data=NaTCCR_r_A_STRAT_DS.NaTCCR_r_A_STRAT_DS}
        {nv-ram-block-element=autosar-variable-in-impl-datatype={root-variable-data-prototype=ExpendableNonVolatile_RamBlock_Core1, target-data-prototype=ExpendableNonVolatile_Ram_Core1/NaTCCR_r_A_STRAT_DS}, written-nv-data=NaTCCR_r_A_STRAT_DS_Rx.NaTCCR_r_A_STRAT_DS}
        {nv-ram-block-element=autosar-variable-in-impl-datatype={root-variable-data-prototype=ExpendableNonVolatile_RamBlock_Core1, target-data-prototype=ExpendableNonVolatile_Ram_Core1/NaTCCR_r_B_STRAT_KF_DS}, read-nv-data=NaTCCR_r_B_STRAT_KF_DS.NaTCCR_r_B_STRAT_KF_DS}
        {nv-ram-block-element=autosar-variable-in-impl-datatype={root-variable-data-prototype=ExpendableNonVolatile_RamBlock_Core1, target-data-prototype=ExpendableNonVolatile_Ram_Core1/NaTCCR_r_B_STRAT_KF_DS}, written-nv-data=NaTCCR_r_B_STRAT_KF_DS_Rx.NaTCCR_r_B_STRAT_KF_DS}
        {nv-ram-block-element=autosar-variable-in-impl-datatype={root-variable-data-prototype=ExpendableNonVolatile_RamBlock_Core1, target-data-prototype=ExpendableNonVolatile_Ram_Core1/NaTCCR_r_B_STRAT_DS}, read-nv-data=NaTCCR_r_B_STRAT_DS.NaTCCR_r_B_STRAT_DS}
        {nv-ram-block-element=autosar-variable-in-impl-datatype={root-variable-data-prototype=ExpendableNonVolatile_RamBlock_Core1, target-data-prototype=ExpendableNonVolatile_Ram_Core1/NaTCCR_r_B_STRAT_DS}, written-nv-data=NaTCCR_r_B_STRAT_DS_Rx.NaTCCR_r_B_STRAT_DS}
        {nv-ram-block-element=autosar-variable-in-impl-datatype={root-variable-data-prototype=ExpendableNonVolatile_RamBlock_Core1, target-data-prototype=ExpendableNonVolatile_Ram_Core1/NaTCCR_r_A_STRAT_KF_DS}, read-nv-data=NaTCCR_r_A_STRAT_KF_DS.NaTCCR_r_A_STRAT_KF_DS}
        {nv-ram-block-element=autosar-variable-in-impl-datatype={root-variable-data-prototype=ExpendableNonVolatile_RamBlock_Core1, target-data-prototype=ExpendableNonVolatile_Ram_Core1/NaTCCR_r_A_STRAT_KF_DS}, written-nv-data=NaTCCR_r_A_STRAT_KF_DS_Rx.NaTCCR_r_A_STRAT_KF_DS}
        {nv-ram-block-element=autosar-variable-in-impl-datatype={root-variable-data-prototype=ExpendableNonVolatile_RamBlock_Core1, target-data-prototype=ExpendableNonVolatile_Ram_Core1/NeHCCR_t_C1_FillTimeEst_DS}, read-nv-data=NeHCCR_t_C1_FillTimeEst_DS.NeHCCR_t_C1_FillTimeEst_DS}
        {nv-ram-block-element=autosar-variable-in-impl-datatype={root-variable-data-prototype=ExpendableNonVolatile_RamBlock_Core1, target-data-prototype=ExpendableNonVolatile_Ram_Core1/NeHCCR_t_C1_FillTimeEst_DS}, written-nv-data=NeHCCR_t_C1_FillTimeEst_DS_Rx.NeHCCR_t_C1_FillTimeEst_DS}
        {nv-ram-block-element=autosar-variable-in-impl-datatype={root-variable-data-prototype=ExpendableNonVolatile_RamBlock_Core1, target-data-prototype=ExpendableNonVolatile_Ram_Core1/NeHCCR_p_C2_TchPt_PresEst_DS}, read-nv-data=NeHCCR_p_C2_TchPt_PresEst_DS.NeHCCR_p_C2_TchPt_PresEst_DS}
        {nv-ram-block-element=autosar-variable-in-impl-datatype={root-variable-data-prototype=ExpendableNonVolatile_RamBlock_Core1, target-data-prototype=ExpendableNonVolatile_Ram_Core1/NeHCCR_p_C2_TchPt_PresEst_DS}, written-nv-data=NeHCCR_p_C2_TchPt_PresEst_DS_Rx.NeHCCR_p_C2_TchPt_PresEst_DS}
        {nv-ram-block-element=autosar-variable-in-impl-datatype={root-variable-data-prototype=ExpendableNonVolatile_RamBlock_Core1, target-data-prototype=ExpendableNonVolatile_Ram_Core1/NeESSR_M_SpinDwnAddtlOffset}, read-nv-data=NeESSR_M_SpinDwnAddtlOffset.NeESSR_M_SpinDwnAddtlOffset}
        {nv-ram-block-element=autosar-variable-in-impl-datatype={root-variable-data-prototype=ExpendableNonVolatile_RamBlock_Core1, target-data-prototype=ExpendableNonVolatile_Ram_Core1/NeESSR_M_SpinDwnAddtlOffset}, written-nv-data=NeESSR_M_SpinDwnAddtlOffset_Rx.NeESSR_M_SpinDwnAddtlOffset}
        {nv-ram-block-element=autosar-variable-in-impl-datatype={root-variable-data-prototype=ExpendableNonVolatile_RamBlock_Core1, target-data-prototype=ExpendableNonVolatile_Ram_Core1/NeESSR_M_SpinUpAddtlOffset}, read-nv-data=NeESSR_M_SpinUpAddtlOffset.NeESSR_M_SpinUpAddtlOffset}
        {nv-ram-block-element=autosar-variable-in-impl-datatype={root-variable-data-prototype=ExpendableNonVolatile_RamBlock_Core1, target-data-prototype=ExpendableNonVolatile_Ram_Core1/NeESSR_M_SpinUpAddtlOffset}, written-nv-data=NeESSR_M_SpinUpAddtlOffset_Rx.NeESSR_M_SpinUpAddtlOffset}
        {nv-ram-block-element=autosar-variable-in-impl-datatype={root-variable-data-prototype=ExpendableNonVolatile_RamBlock_Core1, target-data-prototype=ExpendableNonVolatile_Ram_Core1/NeESSR_g_StrtStpFailRsn}, read-nv-data=NeESSR_g_StrtStpFailRsn.NeESSR_g_StrtStpFailRsn}
        {nv-ram-block-element=autosar-variable-in-impl-datatype={root-variable-data-prototype=ExpendableNonVolatile_RamBlock_Core1, target-data-prototype=ExpendableNonVolatile_Ram_Core1/NeESSR_g_StrtStpFailRsn}, written-nv-data=NeESSR_g_StrtStpFailRsn_Rx.NeESSR_g_StrtStpFailRsn}
        {nv-ram-block-element=autosar-variable-in-impl-datatype={root-variable-data-prototype=ExpendableNonVolatile_RamBlock_Core1, target-data-prototype=ExpendableNonVolatile_Ram_Core1/NeESSR_g_StrtStpFailRsn2}, read-nv-data=NeESSR_g_StrtStpFailRsn2.NeESSR_g_StrtStpFailRsn2}
        {nv-ram-block-element=autosar-variable-in-impl-datatype={root-variable-data-prototype=ExpendableNonVolatile_RamBlock_Core1, target-data-prototype=ExpendableNonVolatile_Ram_Core1/NeESSR_g_StrtStpFailRsn2}, written-nv-data=NeESSR_g_StrtStpFailRsn2_Rx.NeESSR_g_StrtStpFailRsn2}
        {nv-ram-block-element=autosar-variable-in-impl-datatype={root-variable-data-prototype=ExpendableNonVolatile_RamBlock_Core1, target-data-prototype=ExpendableNonVolatile_Ram_Core1/NeESSR_k_EngStpProfAngAdpt}, read-nv-data=NeESSR_k_EngStpProfAngAdpt.NeESSR_k_EngStpProfAngAdpt}
        {nv-ram-block-element=autosar-variable-in-impl-datatype={root-variable-data-prototype=ExpendableNonVolatile_RamBlock_Core1, target-data-prototype=ExpendableNonVolatile_Ram_Core1/NeESSR_k_EngStpProfAngAdpt}, written-nv-data=NeESSR_k_EngStpProfAngAdpt_Rx.NeESSR_k_EngStpProfAngAdpt}
        {nv-ram-block-element=autosar-variable-in-impl-datatype={root-variable-data-prototype=ExpendableNonVolatile_RamBlock_Core1, target-data-prototype=ExpendableNonVolatile_Ram_Core1/NeESSR_k_EngStpProfNiDotGainAdapt}, read-nv-data=NeESSR_k_EngStpProfNiDotGainAdapt.NeESSR_k_EngStpProfNiDotGainAdapt}
        {nv-ram-block-element=autosar-variable-in-impl-datatype={root-variable-data-prototype=ExpendableNonVolatile_RamBlock_Core1, target-data-prototype=ExpendableNonVolatile_Ram_Core1/NeESSR_k_EngStpProfNiDotGainAdapt}, written-nv-data=NeESSR_k_EngStpProfNiDotGainAdapt_Rx.NeESSR_k_EngStpProfNiDotGainAdapt}
        {nv-ram-block-element=autosar-variable-in-impl-datatype={root-variable-data-prototype=ExpendableNonVolatile_RamBlock_Core1, target-data-prototype=ExpendableNonVolatile_Ram_Core1/NeHCCR_t_C2_FillTimeEst_DS}, read-nv-data=NeHCCR_t_C2_FillTimeEst_DS.NeHCCR_t_C2_FillTimeEst_DS}
        {nv-ram-block-element=autosar-variable-in-impl-datatype={root-variable-data-prototype=ExpendableNonVolatile_RamBlock_Core1, target-data-prototype=ExpendableNonVolatile_Ram_Core1/NeHCCR_t_C2_FillTimeEst_DS}, written-nv-data=NeHCCR_t_C2_FillTimeEst_DS_Rx.NeHCCR_t_C2_FillTimeEst_DS}
        {nv-ram-block-element=autosar-variable-in-impl-datatype={root-variable-data-prototype=ExpendableNonVolatile_RamBlock_Core1, target-data-prototype=ExpendableNonVolatile_Ram_Core1/NeHCCR_T_C1_Temp_DS}, read-nv-data=NeHCCR_T_C1_Temp_DS.NeHCCR_T_C1_Temp_DS}
        {nv-ram-block-element=autosar-variable-in-impl-datatype={root-variable-data-prototype=ExpendableNonVolatile_RamBlock_Core1, target-data-prototype=ExpendableNonVolatile_Ram_Core1/NeHCCR_T_C1_Temp_DS}, written-nv-data=NeHCCR_T_C1_Temp_DS_Rx.NeHCCR_T_C1_Temp_DS}
        {nv-ram-block-element=autosar-variable-in-impl-datatype={root-variable-data-prototype=ExpendableNonVolatile_RamBlock_Core1, target-data-prototype=ExpendableNonVolatile_Ram_Core1/NeHCCR_T_C2_Temp_DS}, read-nv-data=NeHCCR_T_C2_Temp_DS.NeHCCR_T_C2_Temp_DS}
        {nv-ram-block-element=autosar-variable-in-impl-datatype={root-variable-data-prototype=ExpendableNonVolatile_RamBlock_Core1, target-data-prototype=ExpendableNonVolatile_Ram_Core1/NeHCCR_T_C2_Temp_DS}, written-nv-data=NeHCCR_T_C2_Temp_DS_Rx.NeHCCR_T_C2_Temp_DS}
        {nv-ram-block-element=autosar-variable-in-impl-datatype={root-variable-data-prototype=ExpendableNonVolatile_RamBlock_Core1, target-data-prototype=ExpendableNonVolatile_Ram_Core1/NeHCCR_l_C1_TchPt_PosnEst_DS}, read-nv-data=NeHCCR_l_C1_TchPt_PosnEst_DS.NeHCCR_l_C1_TchPt_PosnEst_DS}
        {nv-ram-block-element=autosar-variable-in-impl-datatype={root-variable-data-prototype=ExpendableNonVolatile_RamBlock_Core1, target-data-prototype=ExpendableNonVolatile_Ram_Core1/NeHCCR_l_C1_TchPt_PosnEst_DS}, written-nv-data=NeHCCR_l_C1_TchPt_PosnEst_DS_Rx.NeHCCR_l_C1_TchPt_PosnEst_DS}
        {nv-ram-block-element=autosar-variable-in-impl-datatype={root-variable-data-prototype=ExpendableNonVolatile_RamBlock_Core1, target-data-prototype=ExpendableNonVolatile_Ram_Core1/NeHCCR_l_C2_TchPt_PosnEst_DS}, read-nv-data=NeHCCR_l_C2_TchPt_PosnEst_DS.NeHCCR_l_C2_TchPt_PosnEst_DS}
        {nv-ram-block-element=autosar-variable-in-impl-datatype={root-variable-data-prototype=ExpendableNonVolatile_RamBlock_Core1, target-data-prototype=ExpendableNonVolatile_Ram_Core1/NeHCCR_l_C2_TchPt_PosnEst_DS}, written-nv-data=NeHCCR_l_C2_TchPt_PosnEst_DS_Rx.NeHCCR_l_C2_TchPt_PosnEst_DS}
        {nv-ram-block-element=autosar-variable-in-impl-datatype={root-variable-data-prototype=ExpendableNonVolatile_RamBlock_Core1, target-data-prototype=ExpendableNonVolatile_Ram_Core1/NeHCCR_p_C1_TchPt_PresEst_DS}, read-nv-data=NeHCCR_p_C1_TchPt_PresEst_DS.NeHCCR_p_C1_TchPt_PresEst_DS}
        {nv-ram-block-element=autosar-variable-in-impl-datatype={root-variable-data-prototype=ExpendableNonVolatile_RamBlock_Core1, target-data-prototype=ExpendableNonVolatile_Ram_Core1/NeHCCR_p_C1_TchPt_PresEst_DS}, written-nv-data=NeHCCR_p_C1_TchPt_PresEst_DS_Rx.NeHCCR_p_C1_TchPt_PresEst_DS}
        {nv-ram-block-element=autosar-variable-in-impl-datatype={root-variable-data-prototype=ExpendableNonVolatile_RamBlock_Core1, target-data-prototype=ExpendableNonVolatile_Ram_Core1/NeWTAR_Pct_GradeCurrent_xSEM4AeCst}, read-nv-data=NeWTAR_Pct_GradeCurrent_xSEM4AeCst.NeWTAR_Pct_GradeCurrent_xSEM4AeCst}
        {nv-ram-block-element=autosar-variable-in-impl-datatype={root-variable-data-prototype=ExpendableNonVolatile_RamBlock_Core1, target-data-prototype=ExpendableNonVolatile_Ram_Core1/NeWTAR_Pct_GradeCurrent_xSEM4AeCst}, written-nv-data=NeWTAR_Pct_GradeCurrent_xSEM4AeCst_Rx.NeWTAR_Pct_GradeCurrent_xSEM4AeCst}
        {nv-ram-block-element=autosar-variable-in-impl-datatype={root-variable-data-prototype=ExpendableNonVolatile_RamBlock_Core1, target-data-prototype=ExpendableNonVolatile_Ram_Core1/NeLLER_r_NvMin_TireTol_Ratio_FL}, read-nv-data=NeLLER_r_NvMin_TireTol_Ratio_FL.NeLLER_r_NvMin_TireTol_Ratio_FL}
        {nv-ram-block-element=autosar-variable-in-impl-datatype={root-variable-data-prototype=ExpendableNonVolatile_RamBlock_Core1, target-data-prototype=ExpendableNonVolatile_Ram_Core1/NeLLER_r_NvMin_TireTol_Ratio_FL}, written-nv-data=NeLLER_r_NvMin_TireTol_Ratio_FL_Rx.NeLLER_r_NvMin_TireTol_Ratio_FL}
        {nv-ram-block-element=autosar-variable-in-impl-datatype={root-variable-data-prototype=ExpendableNonVolatile_RamBlock_Core1, target-data-prototype=ExpendableNonVolatile_Ram_Core1/NeLLER_r_NvMin_TireTol_Ratio_FR}, read-nv-data=NeLLER_r_NvMin_TireTol_Ratio_FR.NeLLER_r_NvMin_TireTol_Ratio_FR}
        {nv-ram-block-element=autosar-variable-in-impl-datatype={root-variable-data-prototype=ExpendableNonVolatile_RamBlock_Core1, target-data-prototype=ExpendableNonVolatile_Ram_Core1/NeLLER_r_NvMin_TireTol_Ratio_FR}, written-nv-data=NeLLER_r_NvMin_TireTol_Ratio_FR_Rx.NeLLER_r_NvMin_TireTol_Ratio_FR}
        {nv-ram-block-element=autosar-variable-in-impl-datatype={root-variable-data-prototype=ExpendableNonVolatile_RamBlock_Core1, target-data-prototype=ExpendableNonVolatile_Ram_Core1/NeLLER_r_NvMin_TireTol_Ratio_RL}, read-nv-data=NeLLER_r_NvMin_TireTol_Ratio_RL.NeLLER_r_NvMin_TireTol_Ratio_RL}
        {nv-ram-block-element=autosar-variable-in-impl-datatype={root-variable-data-prototype=ExpendableNonVolatile_RamBlock_Core1, target-data-prototype=ExpendableNonVolatile_Ram_Core1/NeLLER_r_NvMin_TireTol_Ratio_RL}, written-nv-data=NeLLER_r_NvMin_TireTol_Ratio_RL_Rx.NeLLER_r_NvMin_TireTol_Ratio_RL}
        {nv-ram-block-element=autosar-variable-in-impl-datatype={root-variable-data-prototype=ExpendableNonVolatile_RamBlock_Core1, target-data-prototype=ExpendableNonVolatile_Ram_Core1/NeLLER_r_NvMin_TireTol_Ratio_RR}, read-nv-data=NeLLER_r_NvMin_TireTol_Ratio_RR.NeLLER_r_NvMin_TireTol_Ratio_RR}
        {nv-ram-block-element=autosar-variable-in-impl-datatype={root-variable-data-prototype=ExpendableNonVolatile_RamBlock_Core1, target-data-prototype=ExpendableNonVolatile_Ram_Core1/NeLLER_r_NvMin_TireTol_Ratio_RR}, written-nv-data=NeLLER_r_NvMin_TireTol_Ratio_RR_Rx.NeLLER_r_NvMin_TireTol_Ratio_RR}
        {nv-ram-block-element=autosar-variable-in-impl-datatype={root-variable-data-prototype=ExpendableNonVolatile_RamBlock_Core1, target-data-prototype=ExpendableNonVolatile_Ram_Core1/NePMPR_n_LT_PsvPmpCmd_AD}, read-nv-data=NePMPR_n_LT_PsvPmpCmd_AD.NePMPR_n_LT_PsvPmpCmd_AD}
        {nv-ram-block-element=autosar-variable-in-impl-datatype={root-variable-data-prototype=ExpendableNonVolatile_RamBlock_Core1, target-data-prototype=ExpendableNonVolatile_Ram_Core1/NePMPR_n_LT_PsvPmpCmd_AD}, written-nv-data=NePMPR_n_LT_PsvPmpCmd_AD_Rx.NePMPR_n_LT_PsvPmpCmd_AD}
        {nv-ram-block-element=autosar-variable-in-impl-datatype={root-variable-data-prototype=ExpendableNonVolatile_RamBlock_Core1, target-data-prototype=ExpendableNonVolatile_Ram_Core1/NePMPR_n_LT_PsvPmp2Cmd_AD}, read-nv-data=NePMPR_n_LT_PsvPmp2Cmd_AD.NePMPR_n_LT_PsvPmp2Cmd_AD}
        {nv-ram-block-element=autosar-variable-in-impl-datatype={root-variable-data-prototype=ExpendableNonVolatile_RamBlock_Core1, target-data-prototype=ExpendableNonVolatile_Ram_Core1/NePMPR_n_LT_PsvPmp2Cmd_AD}, written-nv-data=NePMPR_n_LT_PsvPmp2Cmd_AD_Rx.NePMPR_n_LT_PsvPmp2Cmd_AD}
        {nv-ram-block-element=autosar-variable-in-impl-datatype={root-variable-data-prototype=ExpendableNonVolatile_RamBlock_Core1, target-data-prototype=ExpendableNonVolatile_Ram_Core1/NeSTRR_g_BackupStrtRsn}, read-nv-data=NeSTRR_g_BackupStrtRsn.NeSTRR_g_BackupStrtRsn}
        {nv-ram-block-element=autosar-variable-in-impl-datatype={root-variable-data-prototype=ExpendableNonVolatile_RamBlock_Core1, target-data-prototype=ExpendableNonVolatile_Ram_Core1/NeSTRR_g_BackupStrtRsn}, written-nv-data=NeSTRR_g_BackupStrtRsn_Rx.NeSTRR_g_BackupStrtRsn}
        {nv-ram-block-element=autosar-variable-in-impl-datatype={root-variable-data-prototype=ExpendableNonVolatile_RamBlock_Core1, target-data-prototype=ExpendableNonVolatile_Ram_Core1/NeBPDR_phi_NegSlipIntegrated}, read-nv-data=NeBPDR_phi_NegSlipIntegrated.NeBPDR_phi_NegSlipIntegrated}
        {nv-ram-block-element=autosar-variable-in-impl-datatype={root-variable-data-prototype=ExpendableNonVolatile_RamBlock_Core1, target-data-prototype=ExpendableNonVolatile_Ram_Core1/NeBPDR_phi_NegSlipIntegrated}, written-nv-data=NeBPDR_phi_NegSlipIntegrated_Rx.NeBPDR_phi_NegSlipIntegrated}
        {nv-ram-block-element=autosar-variable-in-impl-datatype={root-variable-data-prototype=ExpendableNonVolatile_RamBlock_Core1, target-data-prototype=ExpendableNonVolatile_Ram_Core1/NeBPDR_phi_PosSlipIntegrated}, read-nv-data=NeBPDR_phi_PosSlipIntegrated.NeBPDR_phi_PosSlipIntegrated}
        {nv-ram-block-element=autosar-variable-in-impl-datatype={root-variable-data-prototype=ExpendableNonVolatile_RamBlock_Core1, target-data-prototype=ExpendableNonVolatile_Ram_Core1/NeBPDR_phi_PosSlipIntegrated}, written-nv-data=NeBPDR_phi_PosSlipIntegrated_Rx.NeBPDR_phi_PosSlipIntegrated}
        {nv-ram-block-element=autosar-variable-in-impl-datatype={root-variable-data-prototype=ExpendableNonVolatile_RamBlock_Core1, target-data-prototype=ExpendableNonVolatile_Ram_Core1/NeTHMR_t_PumpStrtTimeT1}, read-nv-data=NeTHMR_t_PumpStrtTimeT1.NeTHMR_t_PumpStrtTimeT1}
        {nv-ram-block-element=autosar-variable-in-impl-datatype={root-variable-data-prototype=ExpendableNonVolatile_RamBlock_Core1, target-data-prototype=ExpendableNonVolatile_Ram_Core1/NeTHMR_t_PumpStrtTimeT1}, written-nv-data=NeTHMR_t_PumpStrtTimeT1_Rx.NeTHMR_t_PumpStrtTimeT1}
        {nv-ram-block-element=autosar-variable-in-impl-datatype={root-variable-data-prototype=ExpendableNonVolatile_RamBlock_Core1, target-data-prototype=ExpendableNonVolatile_Ram_Core1/NeTHMR_t_PumpRunTmr}, read-nv-data=NeTHMR_t_PumpRunTmr.NeTHMR_t_PumpRunTmr}
        {nv-ram-block-element=autosar-variable-in-impl-datatype={root-variable-data-prototype=ExpendableNonVolatile_RamBlock_Core1, target-data-prototype=ExpendableNonVolatile_Ram_Core1/NeTHMR_t_PumpRunTmr}, written-nv-data=NeTHMR_t_PumpRunTmr_Rx.NeTHMR_t_PumpRunTmr}
        {nv-ram-block-element=autosar-variable-in-impl-datatype={root-variable-data-prototype=ExpendableNonVolatile_RamBlock_Core1, target-data-prototype=ExpendableNonVolatile_Ram_Core1/NeWTAR_Pct_GradeCurrent_xSEM}, read-nv-data=NeWTAR_Pct_GradeCurrent_xSEM.NeWTAR_Pct_GradeCurrent_xSEM}
        {nv-ram-block-element=autosar-variable-in-impl-datatype={root-variable-data-prototype=ExpendableNonVolatile_RamBlock_Core1, target-data-prototype=ExpendableNonVolatile_Ram_Core1/NeWTAR_Pct_GradeCurrent_xSEM}, written-nv-data=NeWTAR_Pct_GradeCurrent_xSEM_Rx.NeWTAR_Pct_GradeCurrent_xSEM}
        {nv-ram-block-element=autosar-variable-in-impl-datatype={root-variable-data-prototype=ExpendableNonVolatile_RamBlock_Core1, target-data-prototype=ExpendableNonVolatile_Ram_Core1/NeWTAR_Pct_GradeCurrent_Raw}, read-nv-data=NeWTAR_Pct_GradeCurrent_Raw.NeWTAR_Pct_GradeCurrent_Raw}
        {nv-ram-block-element=autosar-variable-in-impl-datatype={root-variable-data-prototype=ExpendableNonVolatile_RamBlock_Core1, target-data-prototype=ExpendableNonVolatile_Ram_Core1/NeWTAR_Pct_GradeCurrent_Raw}, written-nv-data=NeWTAR_Pct_GradeCurrent_Raw_Rx.NeWTAR_Pct_GradeCurrent_Raw}
        {nv-ram-block-element=autosar-variable-in-impl-datatype={root-variable-data-prototype=ExpendableNonVolatile_RamBlock_Core1, target-data-prototype=ExpendableNonVolatile_Ram_Core1/NeWTAR_Pct_GradeCurrent}, read-nv-data=NeWTAR_Pct_GradeCurrent.NeWTAR_Pct_GradeCurrent}
        {nv-ram-block-element=autosar-variable-in-impl-datatype={root-variable-data-prototype=ExpendableNonVolatile_RamBlock_Core1, target-data-prototype=ExpendableNonVolatile_Ram_Core1/NeWTAR_Pct_GradeCurrent}, written-nv-data=NeWTAR_Pct_GradeCurrent_Rx.NeWTAR_Pct_GradeCurrent}
        {nv-ram-block-element=autosar-variable-in-impl-datatype={root-variable-data-prototype=ExpendableNonVolatile_RamBlock_Core1, target-data-prototype=ExpendableNonVolatile_Ram_Core1/NeUBTR_t_RealTime_Prev}, read-nv-data=NeUBTR_t_RealTime_Prev.NeUBTR_t_RealTime_Prev}
        {nv-ram-block-element=autosar-variable-in-impl-datatype={root-variable-data-prototype=ExpendableNonVolatile_RamBlock_Core1, target-data-prototype=ExpendableNonVolatile_Ram_Core1/NeUBTR_t_RealTime_Prev}, written-nv-data=NeUBTR_t_RealTime_Prev_Rx.NeUBTR_t_RealTime_Prev}
        {nv-ram-block-element=autosar-variable-in-impl-datatype={root-variable-data-prototype=ExpendableNonVolatile_RamBlock_Core1, target-data-prototype=ExpendableNonVolatile_Ram_Core1/NeUBTR_T_UnderhoodTempPred_Prev}, read-nv-data=NeUBTR_T_UnderhoodTempPred_Prev.NeUBTR_T_UnderhoodTempPred_Prev}
        {nv-ram-block-element=autosar-variable-in-impl-datatype={root-variable-data-prototype=ExpendableNonVolatile_RamBlock_Core1, target-data-prototype=ExpendableNonVolatile_Ram_Core1/NeUBTR_T_UnderhoodTempPred_Prev}, written-nv-data=NeUBTR_T_UnderhoodTempPred_Prev_Rx.NeUBTR_T_UnderhoodTempPred_Prev}
        {nv-ram-block-element=autosar-variable-in-impl-datatype={root-variable-data-prototype=ExpendableNonVolatile_RamBlock_Core1, target-data-prototype=ExpendableNonVolatile_Ram_Core1/NeUBTR_T_BeltTempPred_Prev}, read-nv-data=NeUBTR_T_BeltTempPred_Prev.NeUBTR_T_BeltTempPred_Prev}
        {nv-ram-block-element=autosar-variable-in-impl-datatype={root-variable-data-prototype=ExpendableNonVolatile_RamBlock_Core1, target-data-prototype=ExpendableNonVolatile_Ram_Core1/NeUBTR_T_BeltTempPred_Prev}, written-nv-data=NeUBTR_T_BeltTempPred_Prev_Rx.NeUBTR_T_BeltTempPred_Prev}
        {nv-ram-block-element=autosar-variable-in-impl-datatype={root-variable-data-prototype=ExpendableNonVolatile_RamBlock_Core1, target-data-prototype=ExpendableNonVolatile_Ram_Core1/NeCSDR_phi_C2SlipIntegrated}, read-nv-data=NeCSDR_phi_C2SlipIntegrated.NeCSDR_phi_C2SlipIntegrated}
        {nv-ram-block-element=autosar-variable-in-impl-datatype={root-variable-data-prototype=ExpendableNonVolatile_RamBlock_Core1, target-data-prototype=ExpendableNonVolatile_Ram_Core1/NeCSDR_phi_C2SlipIntegrated}, written-nv-data=NeCSDR_phi_C2SlipIntegrated_Rx.NeCSDR_phi_C2SlipIntegrated}
        {nv-ram-block-element=autosar-variable-in-impl-datatype={root-variable-data-prototype=ExpendableNonVolatile_RamBlock_Core1, target-data-prototype=ExpendableNonVolatile_Ram_Core1/NeSTRR_t_RealTime_EngOff}, read-nv-data=NeSTRR_t_RealTime_EngOff.NeSTRR_t_RealTime_EngOff}
        {nv-ram-block-element=autosar-variable-in-impl-datatype={root-variable-data-prototype=ExpendableNonVolatile_RamBlock_Core1, target-data-prototype=ExpendableNonVolatile_Ram_Core1/NeSTRR_t_RealTime_EngOff}, written-nv-data=NeSTRR_t_RealTime_EngOff_Rx.NeSTRR_t_RealTime_EngOff}
        {nv-ram-block-element=autosar-variable-in-impl-datatype={root-variable-data-prototype=ExpendableNonVolatile_RamBlock_Core1, target-data-prototype=ExpendableNonVolatile_Ram_Core1/NeCSDR_phi_C1SlipIntegrated}, read-nv-data=NeCSDR_phi_C1SlipIntegrated.NeCSDR_phi_C1SlipIntegrated}
        {nv-ram-block-element=autosar-variable-in-impl-datatype={root-variable-data-prototype=ExpendableNonVolatile_RamBlock_Core1, target-data-prototype=ExpendableNonVolatile_Ram_Core1/NeCSDR_phi_C1SlipIntegrated}, written-nv-data=NeCSDR_phi_C1SlipIntegrated_Rx.NeCSDR_phi_C1SlipIntegrated}
        {nv-ram-block-element=autosar-variable-in-impl-datatype={root-variable-data-prototype=ExpendableNonVolatile_RamBlock_Core1, target-data-prototype=ExpendableNonVolatile_Ram_Core1/NeTFTR_t_GenRealTime_Prev}, read-nv-data=NeTFTR_t_GenRealTime_Prev.NeTFTR_t_GenRealTime_Prev}
        {nv-ram-block-element=autosar-variable-in-impl-datatype={root-variable-data-prototype=ExpendableNonVolatile_RamBlock_Core1, target-data-prototype=ExpendableNonVolatile_Ram_Core1/NeTFTR_t_GenRealTime_Prev}, written-nv-data=NeTFTR_t_GenRealTime_Prev_Rx.NeTFTR_t_GenRealTime_Prev}
        {nv-ram-block-element=autosar-variable-in-impl-datatype={root-variable-data-prototype=ExpendableNonVolatile_RamBlock_Core1, target-data-prototype=ExpendableNonVolatile_Ram_Core1/NeTFTR_T_TransOilTempPred_Prev}, read-nv-data=NeTFTR_T_TransOilTempPred_Prev.NeTFTR_T_TransOilTempPred_Prev}
        {nv-ram-block-element=autosar-variable-in-impl-datatype={root-variable-data-prototype=ExpendableNonVolatile_RamBlock_Core1, target-data-prototype=ExpendableNonVolatile_Ram_Core1/NeTFTR_T_TransOilTempPred_Prev}, written-nv-data=NeTFTR_T_TransOilTempPred_Prev_Rx.NeTFTR_T_TransOilTempPred_Prev}
        {nv-ram-block-element=autosar-variable-in-impl-datatype={root-variable-data-prototype=ExpendableNonVolatile_RamBlock_Core1, target-data-prototype=ExpendableNonVolatile_Ram_Core1/NeTFTR_T_GenOilTempEst_Prev}, read-nv-data=NeTFTR_T_GenOilTempEst_Prev.NeTFTR_T_GenOilTempEst_Prev}
        {nv-ram-block-element=autosar-variable-in-impl-datatype={root-variable-data-prototype=ExpendableNonVolatile_RamBlock_Core1, target-data-prototype=ExpendableNonVolatile_Ram_Core1/NeTFTR_T_GenOilTempEst_Prev}, written-nv-data=NeTFTR_T_GenOilTempEst_Prev_Rx.NeTFTR_T_GenOilTempEst_Prev}
        {nv-ram-block-element=autosar-variable-in-impl-datatype={root-variable-data-prototype=ExpendableNonVolatile_RamBlock_Core1, target-data-prototype=ExpendableNonVolatile_Ram_Core1/NeTFTR_t_RealTime_Prev}, read-nv-data=NeTFTR_t_RealTime_Prev.NeTFTR_t_RealTime_Prev}
        {nv-ram-block-element=autosar-variable-in-impl-datatype={root-variable-data-prototype=ExpendableNonVolatile_RamBlock_Core1, target-data-prototype=ExpendableNonVolatile_Ram_Core1/NeTFTR_t_RealTime_Prev}, written-nv-data=NeTFTR_t_RealTime_Prev_Rx.NeTFTR_t_RealTime_Prev}
        {nv-ram-block-element=autosar-variable-in-impl-datatype={root-variable-data-prototype=ExpendableNonVolatile_RamBlock_Core1, target-data-prototype=ExpendableNonVolatile_Ram_Core1/NeSTRR_g_ImmedStopRsn}, read-nv-data=NeSTRR_g_ImmedStopRsn.NeSTRR_g_ImmedStopRsn}
        {nv-ram-block-element=autosar-variable-in-impl-datatype={root-variable-data-prototype=ExpendableNonVolatile_RamBlock_Core1, target-data-prototype=ExpendableNonVolatile_Ram_Core1/NeSTRR_g_ImmedStopRsn}, written-nv-data=NeSTRR_g_ImmedStopRsn_Rx.NeSTRR_g_ImmedStopRsn}
        {nv-ram-block-element=autosar-variable-in-impl-datatype={root-variable-data-prototype=ExpendableNonVolatile_RamBlock_Core1, target-data-prototype=ExpendableNonVolatile_Ram_Core1/NeSTRR_g_BumpStrtRsn}, read-nv-data=NeSTRR_g_BumpStrtRsn.NeSTRR_g_BumpStrtRsn}
        {nv-ram-block-element=autosar-variable-in-impl-datatype={root-variable-data-prototype=ExpendableNonVolatile_RamBlock_Core1, target-data-prototype=ExpendableNonVolatile_Ram_Core1/NeSTRR_g_BumpStrtRsn}, written-nv-data=NeSTRR_g_BumpStrtRsn_Rx.NeSTRR_g_BumpStrtRsn}
        {nv-ram-block-element=autosar-variable-in-impl-datatype={root-variable-data-prototype=ExpendableNonVolatile_RamBlock_Core1, target-data-prototype=ExpendableNonVolatile_Ram_Core1/NeRCVR_Cnt_LTR_CntrlrShtDwn_Cycles}, read-nv-data=NeRCVR_Cnt_LTR_CntrlrShtDwn_Cycles.NeRCVR_Cnt_LTR_CntrlrShtDwn_Cycles}
        {nv-ram-block-element=autosar-variable-in-impl-datatype={root-variable-data-prototype=ExpendableNonVolatile_RamBlock_Core1, target-data-prototype=ExpendableNonVolatile_Ram_Core1/NeRCVR_Cnt_LTR_CntrlrShtDwn_Cycles}, written-nv-data=NeRCVR_Cnt_LTR_CntrlrShtDwn_Cycles_Rx.NeRCVR_Cnt_LTR_CntrlrShtDwn_Cycles}
        {nv-ram-block-element=autosar-variable-in-impl-datatype={root-variable-data-prototype=ExpendableNonVolatile_RamBlock_Core1, target-data-prototype=ExpendableNonVolatile_Ram_Core1/NeRCVR_Cnt_HtrCore_CntrlrShtDwn_Cycles}, read-nv-data=NeRCVR_Cnt_HtrCore_CntrlrShtDwn_Cycles.NeRCVR_Cnt_HtrCore_CntrlrShtDwn_Cycles}
        {nv-ram-block-element=autosar-variable-in-impl-datatype={root-variable-data-prototype=ExpendableNonVolatile_RamBlock_Core1, target-data-prototype=ExpendableNonVolatile_Ram_Core1/NeRCVR_Cnt_HtrCore_CntrlrShtDwn_Cycles}, written-nv-data=NeRCVR_Cnt_HtrCore_CntrlrShtDwn_Cycles_Rx.NeRCVR_Cnt_HtrCore_CntrlrShtDwn_Cycles}
        {nv-ram-block-element=autosar-variable-in-impl-datatype={root-variable-data-prototype=ExpendableNonVolatile_RamBlock_Core1, target-data-prototype=ExpendableNonVolatile_Ram_Core1/NeRCVR_Cnt_HTL_CntrlrShtDwn_Cycles}, read-nv-data=NeRCVR_Cnt_HTL_CntrlrShtDwn_Cycles.NeRCVR_Cnt_HTL_CntrlrShtDwn_Cycles}
        {nv-ram-block-element=autosar-variable-in-impl-datatype={root-variable-data-prototype=ExpendableNonVolatile_RamBlock_Core1, target-data-prototype=ExpendableNonVolatile_Ram_Core1/NeRCVR_Cnt_HTL_CntrlrShtDwn_Cycles}, written-nv-data=NeRCVR_Cnt_HTL_CntrlrShtDwn_Cycles_Rx.NeRCVR_Cnt_HTL_CntrlrShtDwn_Cycles}
        {nv-ram-block-element=autosar-variable-in-impl-datatype={root-variable-data-prototype=ExpendableNonVolatile_RamBlock_Core1, target-data-prototype=ExpendableNonVolatile_Ram_Core1/NeRCVR_Cnt_CPV_CntrlrShtDwn_Cycles}, read-nv-data=NeRCVR_Cnt_CPV_CntrlrShtDwn_Cycles.NeRCVR_Cnt_CPV_CntrlrShtDwn_Cycles}
        {nv-ram-block-element=autosar-variable-in-impl-datatype={root-variable-data-prototype=ExpendableNonVolatile_RamBlock_Core1, target-data-prototype=ExpendableNonVolatile_Ram_Core1/NeRCVR_Cnt_CPV_CntrlrShtDwn_Cycles}, written-nv-data=NeRCVR_Cnt_CPV_CntrlrShtDwn_Cycles_Rx.NeRCVR_Cnt_CPV_CntrlrShtDwn_Cycles}
        {nv-ram-block-element=autosar-variable-in-impl-datatype={root-variable-data-prototype=ExpendableNonVolatile_RamBlock_Core1, target-data-prototype=ExpendableNonVolatile_Ram_Core1/NeHCCR_Cnt_C2CShifts_TchPtLrn}, read-nv-data=NeHCCR_Cnt_C2CShifts_TchPtLrn.NeHCCR_Cnt_C2CShifts_TchPtLrn}
        {nv-ram-block-element=autosar-variable-in-impl-datatype={root-variable-data-prototype=ExpendableNonVolatile_RamBlock_Core1, target-data-prototype=ExpendableNonVolatile_Ram_Core1/NeHCCR_Cnt_C2CShifts_TchPtLrn}, written-nv-data=NeHCCR_Cnt_C2CShifts_TchPtLrn_Rx.NeHCCR_Cnt_C2CShifts_TchPtLrn}
        {nv-ram-block-element=autosar-variable-in-impl-datatype={root-variable-data-prototype=ExpendableNonVolatile_RamBlock_Core1, target-data-prototype=ExpendableNonVolatile_Ram_Core1/NeHCCR_Cnt_AllC2CShifts}, read-nv-data=NeHCCR_Cnt_AllC2CShifts.NeHCCR_Cnt_AllC2CShifts}
        {nv-ram-block-element=autosar-variable-in-impl-datatype={root-variable-data-prototype=ExpendableNonVolatile_RamBlock_Core1, target-data-prototype=ExpendableNonVolatile_Ram_Core1/NeHCCR_Cnt_AllC2CShifts}, written-nv-data=NeHCCR_Cnt_AllC2CShifts_Rx.NeHCCR_Cnt_AllC2CShifts}
        {nv-ram-block-element=autosar-variable-in-impl-datatype={root-variable-data-prototype=ExpendableNonVolatile_RamBlock_Core1, target-data-prototype=ExpendableNonVolatile_Ram_Core1/NeESSR_Cnt_AdptInitValue}, read-nv-data=NeESSR_Cnt_AdptInitValue.NeESSR_Cnt_AdptInitValue}
        {nv-ram-block-element=autosar-variable-in-impl-datatype={root-variable-data-prototype=ExpendableNonVolatile_RamBlock_Core1, target-data-prototype=ExpendableNonVolatile_Ram_Core1/NeESSR_Cnt_AdptInitValue}, written-nv-data=NeESSR_Cnt_AdptInitValue_Rx.NeESSR_Cnt_AdptInitValue}
        {nv-ram-block-element=autosar-variable-in-impl-datatype={root-variable-data-prototype=ExpendableNonVolatile_RamBlock_Core1, target-data-prototype=ExpendableNonVolatile_Ram_Core1/NeBPDR_Cnt_BeltSlip_MFOP}, read-nv-data=NeBPDR_Cnt_BeltSlip_MFOP.NeBPDR_Cnt_BeltSlip_MFOP}
        {nv-ram-block-element=autosar-variable-in-impl-datatype={root-variable-data-prototype=ExpendableNonVolatile_RamBlock_Core1, target-data-prototype=ExpendableNonVolatile_Ram_Core1/NeBPDR_Cnt_BeltSlip_MFOP}, written-nv-data=NeBPDR_Cnt_BeltSlip_MFOP_Rx.NeBPDR_Cnt_BeltSlip_MFOP}
        {nv-ram-block-element=autosar-variable-in-impl-datatype={root-variable-data-prototype=ExpendableNonVolatile_RamBlock_Core1, target-data-prototype=ExpendableNonVolatile_Ram_Core1/NeBPSD_Cnt_BrkPdlLvlOneCktHi_MFOP}, read-nv-data=NeBPSD_Cnt_BrkPdlLvlOneCktHi_MFOP.NeBPSD_Cnt_BrkPdlLvlOneCktHi_MFOP}
        {nv-ram-block-element=autosar-variable-in-impl-datatype={root-variable-data-prototype=ExpendableNonVolatile_RamBlock_Core1, target-data-prototype=ExpendableNonVolatile_Ram_Core1/NeBPSD_Cnt_BrkPdlLvlOneCktHi_MFOP}, written-nv-data=NeBPSD_Cnt_BrkPdlLvlOneCktHi_MFOP_Rx.NeBPSD_Cnt_BrkPdlLvlOneCktHi_MFOP}
        {nv-ram-block-element=autosar-variable-in-impl-datatype={root-variable-data-prototype=ExpendableNonVolatile_RamBlock_Core1, target-data-prototype=ExpendableNonVolatile_Ram_Core1/NeBPSD_Cnt_BrkPdlLvlOneCktLo_MFOP}, read-nv-data=NeBPSD_Cnt_BrkPdlLvlOneCktLo_MFOP.NeBPSD_Cnt_BrkPdlLvlOneCktLo_MFOP}
        {nv-ram-block-element=autosar-variable-in-impl-datatype={root-variable-data-prototype=ExpendableNonVolatile_RamBlock_Core1, target-data-prototype=ExpendableNonVolatile_Ram_Core1/NeBPSD_Cnt_BrkPdlLvlOneCktLo_MFOP}, written-nv-data=NeBPSD_Cnt_BrkPdlLvlOneCktLo_MFOP_Rx.NeBPSD_Cnt_BrkPdlLvlOneCktLo_MFOP}
        {nv-ram-block-element=autosar-variable-in-impl-datatype={root-variable-data-prototype=ExpendableNonVolatile_RamBlock_Core1, target-data-prototype=ExpendableNonVolatile_Ram_Core1/NeBPSD_Cnt_BrkPdlSnsPerf_MFOP}, read-nv-data=NeBPSD_Cnt_BrkPdlSnsPerf_MFOP.NeBPSD_Cnt_BrkPdlSnsPerf_MFOP}
        {nv-ram-block-element=autosar-variable-in-impl-datatype={root-variable-data-prototype=ExpendableNonVolatile_RamBlock_Core1, target-data-prototype=ExpendableNonVolatile_Ram_Core1/NeBPSD_Cnt_BrkPdlSnsPerf_MFOP}, written-nv-data=NeBPSD_Cnt_BrkPdlSnsPerf_MFOP_Rx.NeBPSD_Cnt_BrkPdlSnsPerf_MFOP}
        {nv-ram-block-element=autosar-variable-in-impl-datatype={root-variable-data-prototype=ExpendableNonVolatile_RamBlock_Core1, target-data-prototype=ExpendableNonVolatile_Ram_Core1/NeTCCR_b_UpdLaw_DS}, read-nv-data=NeTCCR_b_UpdLaw_DS.NeTCCR_b_UpdLaw_DS}
        {nv-ram-block-element=autosar-variable-in-impl-datatype={root-variable-data-prototype=ExpendableNonVolatile_RamBlock_Core1, target-data-prototype=ExpendableNonVolatile_Ram_Core1/NeTCCR_b_UpdLaw_DS}, written-nv-data=NeTCCR_b_UpdLaw_DS_Rx.NeTCCR_b_UpdLaw_DS}
        {nv-ram-block-element=autosar-variable-in-impl-datatype={root-variable-data-prototype=ExpendableNonVolatile_RamBlock_Core1, target-data-prototype=ExpendableNonVolatile_Ram_Core1/NeSTFR_b_FailedStrtPrevCycle}, read-nv-data=NeSTFR_b_FailedStrtPrevCycle.NeSTFR_b_FailedStrtPrevCycle}
        {nv-ram-block-element=autosar-variable-in-impl-datatype={root-variable-data-prototype=ExpendableNonVolatile_RamBlock_Core1, target-data-prototype=ExpendableNonVolatile_Ram_Core1/NeSTFR_b_FailedStrtPrevCycle}, written-nv-data=NeSTFR_b_FailedStrtPrevCycle_Rx.NeSTFR_b_FailedStrtPrevCycle}
        {nv-ram-block-element=autosar-variable-in-impl-datatype={root-variable-data-prototype=ExpendableNonVolatile_RamBlock_Core1, target-data-prototype=ExpendableNonVolatile_Ram_Core1/NeSTRR_b_RealTime_EngOFF_FA}, read-nv-data=NeSTRR_b_RealTime_EngOFF_FA.NeSTRR_b_RealTime_EngOFF_FA}
        {nv-ram-block-element=autosar-variable-in-impl-datatype={root-variable-data-prototype=ExpendableNonVolatile_RamBlock_Core1, target-data-prototype=ExpendableNonVolatile_Ram_Core1/NeSTRR_b_RealTime_EngOFF_FA}, written-nv-data=NeSTRR_b_RealTime_EngOFF_FA_Rx.NeSTRR_b_RealTime_EngOFF_FA}
        {nv-ram-block-element=autosar-variable-in-impl-datatype={root-variable-data-prototype=ExpendableNonVolatile_RamBlock_Core1, target-data-prototype=ExpendableNonVolatile_Ram_Core1/NeSTRR_b_StrtFailLowPwrLtch}, read-nv-data=NeSTRR_b_StrtFailLowPwrLtch.NeSTRR_b_StrtFailLowPwrLtch}
        {nv-ram-block-element=autosar-variable-in-impl-datatype={root-variable-data-prototype=ExpendableNonVolatile_RamBlock_Core1, target-data-prototype=ExpendableNonVolatile_Ram_Core1/NeSTRR_b_StrtFailLowPwrLtch}, written-nv-data=NeSTRR_b_StrtFailLowPwrLtch_Rx.NeSTRR_b_StrtFailLowPwrLtch}
        {nv-ram-block-element=autosar-variable-in-impl-datatype={root-variable-data-prototype=ExpendableNonVolatile_RamBlock_Core1, target-data-prototype=ExpendableNonVolatile_Ram_Core1/NePMPR_e_LTPsvPump_PstRnSt}, read-nv-data=NePMPR_e_LTPsvPump_PstRnSt.NePMPR_e_LTPsvPump_PstRnSt}
        {nv-ram-block-element=autosar-variable-in-impl-datatype={root-variable-data-prototype=ExpendableNonVolatile_RamBlock_Core1, target-data-prototype=ExpendableNonVolatile_Ram_Core1/NePMPR_e_LTPsvPump_PstRnSt}, written-nv-data=NePMPR_e_LTPsvPump_PstRnSt_Rx.NePMPR_e_LTPsvPump_PstRnSt}
        {nv-ram-block-element=autosar-variable-in-impl-datatype={root-variable-data-prototype=ExpendableNonVolatile_RamBlock_Core1, target-data-prototype=ExpendableNonVolatile_Ram_Core1/NePMPR_e_LTPsvPump2_PstRnSt}, read-nv-data=NePMPR_e_LTPsvPump2_PstRnSt.NePMPR_e_LTPsvPump2_PstRnSt}
        {nv-ram-block-element=autosar-variable-in-impl-datatype={root-variable-data-prototype=ExpendableNonVolatile_RamBlock_Core1, target-data-prototype=ExpendableNonVolatile_Ram_Core1/NePMPR_e_LTPsvPump2_PstRnSt}, written-nv-data=NePMPR_e_LTPsvPump2_PstRnSt_Rx.NePMPR_e_LTPsvPump2_PstRnSt}
        {nv-ram-block-element=autosar-variable-in-impl-datatype={root-variable-data-prototype=ExpendableNonVolatile_RamBlock_Core1, target-data-prototype=ExpendableNonVolatile_Ram_Core1/NePMPR_e_LT_PsvPmp2_PostRunCmd_AD}, read-nv-data=NePMPR_e_LT_PsvPmp2_PostRunCmd_AD.NePMPR_e_LT_PsvPmp2_PostRunCmd_AD}
        {nv-ram-block-element=autosar-variable-in-impl-datatype={root-variable-data-prototype=ExpendableNonVolatile_RamBlock_Core1, target-data-prototype=ExpendableNonVolatile_Ram_Core1/NePMPR_e_LT_PsvPmp2_PostRunCmd_AD}, written-nv-data=NePMPR_e_LT_PsvPmp2_PostRunCmd_AD_Rx.NePMPR_e_LT_PsvPmp2_PostRunCmd_AD}
        {nv-ram-block-element=autosar-variable-in-impl-datatype={root-variable-data-prototype=ExpendableNonVolatile_RamBlock_Core1, target-data-prototype=ExpendableNonVolatile_Ram_Core1/NeTMIR_e_HCP_LTP_FanAftRun_Rq}, read-nv-data=NeTMIR_e_HCP_LTP_FanAftRun_Rq.NeTMIR_e_HCP_LTP_FanAftRun_Rq}
        {nv-ram-block-element=autosar-variable-in-impl-datatype={root-variable-data-prototype=ExpendableNonVolatile_RamBlock_Core1, target-data-prototype=ExpendableNonVolatile_Ram_Core1/NeTMIR_e_HCP_LTP_FanAftRun_Rq}, written-nv-data=NeTMIR_e_HCP_LTP_FanAftRun_Rq_Rx.NeTMIR_e_HCP_LTP_FanAftRun_Rq}
        {nv-ram-block-element=autosar-variable-in-impl-datatype={root-variable-data-prototype=ExpendableNonVolatile_RamBlock_Core1, target-data-prototype=ExpendableNonVolatile_Ram_Core1/NePMPR_e_LT_PsvPmp_PostRunCmd_AD}, read-nv-data=NePMPR_e_LT_PsvPmp_PostRunCmd_AD.NePMPR_e_LT_PsvPmp_PostRunCmd_AD}
        {nv-ram-block-element=autosar-variable-in-impl-datatype={root-variable-data-prototype=ExpendableNonVolatile_RamBlock_Core1, target-data-prototype=ExpendableNonVolatile_Ram_Core1/NePMPR_e_LT_PsvPmp_PostRunCmd_AD}, written-nv-data=NePMPR_e_LT_PsvPmp_PostRunCmd_AD_Rx.NePMPR_e_LT_PsvPmp_PostRunCmd_AD}
        {nv-ram-block-element=autosar-variable-in-impl-datatype={root-variable-data-prototype=ExpendableNonVolatile_RamBlock_Core1, target-data-prototype=ExpendableNonVolatile_Ram_Core1/NeHCCR_b_C2TchPt_DtctFlg_DS}, read-nv-data=NeHCCR_b_C2TchPt_DtctFlg_DS.NeHCCR_b_C2TchPt_DtctFlg_DS}
        {nv-ram-block-element=autosar-variable-in-impl-datatype={root-variable-data-prototype=ExpendableNonVolatile_RamBlock_Core1, target-data-prototype=ExpendableNonVolatile_Ram_Core1/NeHCCR_b_C2TchPt_DtctFlg_DS}, written-nv-data=NeHCCR_b_C2TchPt_DtctFlg_DS_Rx.NeHCCR_b_C2TchPt_DtctFlg_DS}
        {nv-ram-block-element=autosar-variable-in-impl-datatype={root-variable-data-prototype=ExpendableNonVolatile_RamBlock_Core1, target-data-prototype=ExpendableNonVolatile_Ram_Core1/NeHCCR_b_C1TchPt_DtctFlg_DS}, read-nv-data=NeHCCR_b_C1TchPt_DtctFlg_DS.NeHCCR_b_C1TchPt_DtctFlg_DS}
        {nv-ram-block-element=autosar-variable-in-impl-datatype={root-variable-data-prototype=ExpendableNonVolatile_RamBlock_Core1, target-data-prototype=ExpendableNonVolatile_Ram_Core1/NeHCCR_b_C1TchPt_DtctFlg_DS}, written-nv-data=NeHCCR_b_C1TchPt_DtctFlg_DS_Rx.NeHCCR_b_C1TchPt_DtctFlg_DS}
      nv block needs NvBlockNeeds: calc-ram-block-crc=false, check-static-block-id=false, readonly=false, resistant-to-changed-sw=false, restore-at-start=true, store-at-shutdown=true, store-cyclic=false, store-emergency=false, store-immediate=false, use-auto-validation-at-shut-down=false, use-crc-comp-mechanism=true, write-only-once=false, write-verification=false
      ram block ExpendableNonVolatile_RamBlock_Core1: type=ExpendableNonVolatile_Ram_Core1, init-value={short-label=ExpendableNonVolatile_Ram_Core1, fields=[NaTCCR_r_A_STRAT_DS_KF:[ArrayElement0:0, ArrayElement1:0, ArrayElement2:0, ArrayElement3:0, ArrayElement4:0, ArrayElement5:0, ArrayElement6:0, ArrayElement7:0, ArrayElement8:0, ArrayElement9:0, ArrayElement10:0, ArrayElement11:0, ArrayElement12:0, ArrayElement13:0, ArrayElement14:0, ArrayElement15:0, ArrayElement16:0, ArrayElement17:0, ArrayElement18:0, ArrayElement19:0, ArrayElement20:0, ArrayElement21:0], NaTCCR_r_A_STRAT_DS:[ArrayElement0:0, ArrayElement1:0, ArrayElement2:0, ArrayElement3:0, ArrayElement4:0, ArrayElement5:0, ArrayElement6:0, ArrayElement7:0, ArrayElement8:0, ArrayElement9:0, ArrayElement10:0, ArrayElement11:0, ArrayElement12:0, ArrayElement13:0, ArrayElement14:0, ArrayElement15:0, ArrayElement16:0, ArrayElement17:0, ArrayElement18:0, ArrayElement19:0, ArrayElement20:0, ArrayElement21:0], NaTCCR_r_B_STRAT_KF_DS:[ArrayElement0:0, ArrayElement1:0, ArrayElement2:0, ArrayElement3:0, ArrayElement4:0, ArrayElement5:0, ArrayElement6:0, ArrayElement7:0, ArrayElement8:0, ArrayElement9:0, ArrayElement10:0, ArrayElement11:0, ArrayElement12:0, ArrayElement13:0, ArrayElement14:0, ArrayElement15:0, ArrayElement16:0, ArrayElement17:0, ArrayElement18:0, ArrayElement19:0, ArrayElement20:0, ArrayElement21:0], NaTCCR_r_B_STRAT_DS:[ArrayElement0:0, ArrayElement1:0, ArrayElement2:0, ArrayElement3:0, ArrayElement4:0, ArrayElement5:0, ArrayElement6:0, ArrayElement7:0, ArrayElement8:0, ArrayElement9:0, ArrayElement10:0, ArrayElement11:0, ArrayElement12:0, ArrayElement13:0, ArrayElement14:0, ArrayElement15:0, ArrayElement16:0, ArrayElement17:0, ArrayElement18:0, ArrayElement19:0, ArrayElement20:0, ArrayElement21:0], NaTCCR_r_A_STRAT_KF_DS:[ArrayElement0:0, ArrayElement1:0, ArrayElement2:0, ArrayElement3:0, ArrayElement4:0, ArrayElement5:0, ArrayElement6:0, ArrayElement7:0, ArrayElement8:0, ArrayElement9:0, ArrayElement10:0, ArrayElement11:0, ArrayElement12:0, ArrayElement13:0, ArrayElement14:0, ArrayElement15:0, ArrayElement16:0, ArrayElement17:0, ArrayElement18:0, ArrayElement19:0, ArrayElement20:0, ArrayElement21:0], NeHCCR_t_C1_FillTimeEst_DS:4294967295, NeHCCR_p_C2_TchPt_PresEst_DS:4294967295, NeESSR_M_SpinDwnAddtlOffset:0, NeESSR_M_SpinUpAddtlOffset:0, NeESSR_g_StrtStpFailRsn:4294967295, NeESSR_g_StrtStpFailRsn2:0, NeESSR_k_EngStpProfAngAdpt:0, NeESSR_k_EngStpProfNiDotGainAdapt:0, NeHCCR_t_C2_FillTimeEst_DS:4294967295, NeHCCR_T_C1_Temp_DS:4294967295, NeHCCR_T_C2_Temp_DS:4294967295, NeHCCR_l_C1_TchPt_PosnEst_DS:4294967295, NeHCCR_l_C2_TchPt_PosnEst_DS:4294967295, NeHCCR_p_C1_TchPt_PresEst_DS:4294967295, NeWTAR_Pct_GradeCurrent_xSEM4AeCst:0, NeLLER_r_NvMin_TireTol_Ratio_FL:0, NeLLER_r_NvMin_TireTol_Ratio_FR:0, NeLLER_r_NvMin_TireTol_Ratio_RL:0, NeLLER_r_NvMin_TireTol_Ratio_RR:0, NePMPR_n_LT_PsvPmpCmd_AD:0, NePMPR_n_LT_PsvPmp2Cmd_AD:0, NeSTRR_g_BackupStrtRsn:0, NeBPDR_phi_NegSlipIntegrated:0, NeBPDR_phi_PosSlipIntegrated:0, NeTHMR_t_PumpStrtTimeT1:0, NeTHMR_t_PumpRunTmr:0, NeWTAR_Pct_GradeCurrent_xSEM:0, NeWTAR_Pct_GradeCurrent_Raw:0, NeWTAR_Pct_GradeCurrent:0, NeUBTR_t_RealTime_Prev:0, NeUBTR_T_UnderhoodTempPred_Prev:0, NeUBTR_T_BeltTempPred_Prev:0, NeCSDR_phi_C2SlipIntegrated:0, NeSTRR_t_RealTime_EngOff:0, NeCSDR_phi_C1SlipIntegrated:0, NeTFTR_t_GenRealTime_Prev:0, NeTFTR_T_TransOilTempPred_Prev:0, NeTFTR_T_GenOilTempEst_Prev:0, NeTFTR_t_RealTime_Prev:0, NeSTRR_g_ImmedStopRsn:4294967295, NeSTRR_g_BumpStrtRsn:0, NeRCVR_Cnt_LTR_CntrlrShtDwn_Cycles:0, NeRCVR_Cnt_HtrCore_CntrlrShtDwn_Cycles:0, NeRCVR_Cnt_HTL_CntrlrShtDwn_Cycles:0, NeRCVR_Cnt_CPV_CntrlrShtDwn_Cycles:0, NeHCCR_Cnt_C2CShifts_TchPtLrn:65535, NeHCCR_Cnt_AllC2CShifts:65535, 0, NeBPDR_Cnt_BeltSlip_MFOP:0, NeBPSD_Cnt_BrkPdlLvlOneCktHi_MFOP:0, NeBPSD_Cnt_BrkPdlLvlOneCktLo_MFOP:0, NeBPSD_Cnt_BrkPdlSnsPerf_MFOP:0, NeTCCR_b_UpdLaw_DS:0, NeSTFR_b_FailedStrtPrevCycle:0, NeSTRR_b_RealTime_EngOFF_FA:0, NeSTRR_b_StrtFailLowPwrLtch:0, NePMPR_e_LTPsvPump_PstRnSt:0, NePMPR_e_LTPsvPump2_PstRnSt:0, NePMPR_e_LT_PsvPmp2_PostRunCmd_AD:0, NeTMIR_e_HCP_LTP_FanAftRun_Rq:0, NePMPR_e_LT_PsvPmp_PostRunCmd_AD:0, NeHCCR_b_C2TchPt_DtctFlg_DS:1, NeHCCR_b_C1TchPt_DtctFlg_DS:1, Reserved1:0, Reserved2:0, Reserved3:0, Reserved4:0, Reserved5:0, Reserved6:0, Reserved7:0, Reserved8:0, Reserved9:0, Reserved10:0, Reserved11:0, Reserved12:0, Reserved13:0, Reserved14:0, Reserved15:0, Reserved16:0, Reserved17:0, Reserved18:0, Reserved19:0, Reserved20:0, Reserved21:0, Reserved22:0, Reserved23:0, Reserved24:0, Reserved25:0, Reserved26:0, Reserved27:0]}
      rom block ExpendableNonVolatile_RomBlock_Core1: type=ExpendableNonVolatile_Rom_Core1, init-value={short-label=ExpendableNonVolatile_Rom_Core1, fields=[NaTCCR_r_A_STRAT_DS_KF:[ArrayElement0:0, ArrayElement1:0, ArrayElement2:0, ArrayElement3:0, ArrayElement4:0, ArrayElement5:0, ArrayElement6:0, ArrayElement7:0, ArrayElement8:0, ArrayElement9:0, ArrayElement10:0, ArrayElement11:0, ArrayElement12:0, ArrayElement13:0, ArrayElement14:0, ArrayElement15:0, ArrayElement16:0, ArrayElement17:0, ArrayElement18:0, ArrayElement19:0, ArrayElement20:0, ArrayElement21:0], NaTCCR_r_A_STRAT_DS:[ArrayElement0:0, ArrayElement1:0, ArrayElement2:0, ArrayElement3:0, ArrayElement4:0, ArrayElement5:0, ArrayElement6:0, ArrayElement7:0, ArrayElement8:0, ArrayElement9:0, ArrayElement10:0, ArrayElement11:0, ArrayElement12:0, ArrayElement13:0, ArrayElement14:0, ArrayElement15:0, ArrayElement16:0, ArrayElement17:0, ArrayElement18:0, ArrayElement19:0, ArrayElement20:0, ArrayElement21:0], NaTCCR_r_B_STRAT_KF_DS:[ArrayElement0:0, ArrayElement1:0, ArrayElement2:0, ArrayElement3:0, ArrayElement4:0, ArrayElement5:0, ArrayElement6:0, ArrayElement7:0, ArrayElement8:0, ArrayElement9:0, ArrayElement10:0, ArrayElement11:0, ArrayElement12:0, ArrayElement13:0, ArrayElement14:0, ArrayElement15:0, ArrayElement16:0, ArrayElement17:0, ArrayElement18:0, ArrayElement19:0, ArrayElement20:0, ArrayElement21:0], NaTCCR_r_B_STRAT_DS:[ArrayElement0:0, ArrayElement1:0, ArrayElement2:0, ArrayElement3:0, ArrayElement4:0, ArrayElement5:0, ArrayElement6:0, ArrayElement7:0, ArrayElement8:0, ArrayElement9:0, ArrayElement10:0, ArrayElement11:0, ArrayElement12:0, ArrayElement13:0, ArrayElement14:0, ArrayElement15:0, ArrayElement16:0, ArrayElement17:0, ArrayElement18:0, ArrayElement19:0, ArrayElement20:0, ArrayElement21:0], NaTCCR_r_A_STRAT_KF_DS:[ArrayElement0:0, ArrayElement1:0, ArrayElement2:0, ArrayElement3:0, ArrayElement4:0, ArrayElement5:0, ArrayElement6:0, ArrayElement7:0, ArrayElement8:0, ArrayElement9:0, ArrayElement10:0, ArrayElement11:0, ArrayElement12:0, ArrayElement13:0, ArrayElement14:0, ArrayElement15:0, ArrayElement16:0, ArrayElement17:0, ArrayElement18:0, ArrayElement19:0, ArrayElement20:0, ArrayElement21:0], NeHCCR_t_C1_FillTimeEst_DS:4294967295, NeHCCR_p_C2_TchPt_PresEst_DS:4294967295, NeESSR_M_SpinDwnAddtlOffset:0, NeESSR_M_SpinUpAddtlOffset:0, NeESSR_g_StrtStpFailRsn:4294967295, NeESSR_g_StrtStpFailRsn2:0, NeESSR_k_EngStpProfAngAdpt:0, NeESSR_k_EngStpProfNiDotGainAdapt:0, NeHCCR_t_C2_FillTimeEst_DS:4294967295, NeHCCR_T_C1_Temp_DS:4294967295, NeHCCR_T_C2_Temp_DS:4294967295, NeHCCR_l_C1_TchPt_PosnEst_DS:4294967295, NeHCCR_l_C2_TchPt_PosnEst_DS:4294967295, NeHCCR_p_C1_TchPt_PresEst_DS:4294967295, NeWTAR_Pct_GradeCurrent_xSEM4AeCst:0, NeLLER_r_NvMin_TireTol_Ratio_FL:0, NeLLER_r_NvMin_TireTol_Ratio_FR:0, NeLLER_r_NvMin_TireTol_Ratio_RL:0, NeLLER_r_NvMin_TireTol_Ratio_RR:0, NePMPR_n_LT_PsvPmpCmd_AD:0, NePMPR_n_LT_PsvPmp2Cmd_AD:0, NeSTRR_g_BackupStrtRsn:0, NeBPDR_phi_NegSlipIntegrated:0, NeBPDR_phi_PosSlipIntegrated:0, NeTHMR_t_PumpStrtTimeT1:0, NeTHMR_t_PumpRunTmr:0, NeWTAR_Pct_GradeCurrent_xSEM:0, NeWTAR_Pct_GradeCurrent_Raw:0, NeWTAR_Pct_GradeCurrent:0, NeUBTR_t_RealTime_Prev:0, NeUBTR_T_UnderhoodTempPred_Prev:0, NeUBTR_T_BeltTempPred_Prev:0, NeCSDR_phi_C2SlipIntegrated:0, NeSTRR_t_RealTime_EngOff:0, NeCSDR_phi_C1SlipIntegrated:0, NeTFTR_t_GenRealTime_Prev:0, NeTFTR_T_TransOilTempPred_Prev:0, NeTFTR_T_GenOilTempEst_Prev:0, NeTFTR_t_RealTime_Prev:0, NeSTRR_g_ImmedStopRsn:4294967295, NeSTRR_g_BumpStrtRsn:0, NeRCVR_Cnt_LTR_CntrlrShtDwn_Cycles:0, NeRCVR_Cnt_HtrCore_CntrlrShtDwn_Cycles:0, NeRCVR_Cnt_HTL_CntrlrShtDwn_Cycles:0, NeRCVR_Cnt_CPV_CntrlrShtDwn_Cycles:0, NeHCCR_Cnt_C2CShifts_TchPtLrn:65535, NeHCCR_Cnt_AllC2CShifts:65535, 0, NeBPDR_Cnt_BeltSlip_MFOP:0, NeBPSD_Cnt_BrkPdlLvlOneCktHi_MFOP:0, NeBPSD_Cnt_BrkPdlLvlOneCktLo_MFOP:0, NeBPSD_Cnt_BrkPdlSnsPerf_MFOP:0, NeTCCR_b_UpdLaw_DS:0, NeSTFR_b_FailedStrtPrevCycle:0, NeSTRR_b_RealTime_EngOFF_FA:0, NeSTRR_b_StrtFailLowPwrLtch:0, NePMPR_e_LTPsvPump_PstRnSt:0, NePMPR_e_LTPsvPump2_PstRnSt:0, NePMPR_e_LT_PsvPmp2_PostRunCmd_AD:0, NeTMIR_e_HCP_LTP_FanAftRun_Rq:0, NePMPR_e_LT_PsvPmp_PostRunCmd_AD:0, NeHCCR_b_C2TchPt_DtctFlg_DS:1, NeHCCR_b_C1TchPt_DtctFlg_DS:1, Reserved1:0, Reserved2:0, Reserved3:0, Reserved4:0, Reserved5:0, Reserved6:0, Reserved7:0, Reserved8:0, Reserved9:0, Reserved10:0, Reserved11:0, Reserved12:0, Reserved13:0, Reserved14:0, Reserved15:0, Reserved16:0, Reserved17:0, Reserved18:0, Reserved19:0, Reserved20:0, Reserved21:0, Reserved22:0, Reserved23:0, Reserved24:0, Reserved25:0, Reserved26:0, Reserved27:0]}
    nv block descriptor CumulativeNonVolatile_Descr_Core1: support-dirty-flag=true
      nv-block-data-mappings:
        {nv-ram-block-element=autosar-variable-in-impl-datatype={root-variable-data-prototype=CumulativeNonVolatile_RamBlock_Core1, target-data-prototype=CumulativeNonVolatile_Ram_Core1/EeRCVR_U_HT_CabVlvSts_Min}, read-nv-data=EeRCVR_U_HT_CabVlvSts_Min.EeRCVR_U_HT_CabVlvSts_Min}
        {nv-ram-block-element=autosar-variable-in-impl-datatype={root-variable-data-prototype=CumulativeNonVolatile_RamBlock_Core1, target-data-prototype=CumulativeNonVolatile_Ram_Core1/EeRCVR_U_HT_CabVlvSts_Min}, written-nv-data=EeRCVR_U_HT_CabVlvSts_Min_Rx.EeRCVR_U_HT_CabVlvSts_Min}
        {nv-ram-block-element=autosar-variable-in-impl-datatype={root-variable-data-prototype=CumulativeNonVolatile_RamBlock_Core1, target-data-prototype=CumulativeNonVolatile_Ram_Core1/EeRCVR_U_HT_CabVlvSts_Max}, read-nv-data=EeRCVR_U_HT_CabVlvSts_Max.EeRCVR_U_HT_CabVlvSts_Max}
        {nv-ram-block-element=autosar-variable-in-impl-datatype={root-variable-data-prototype=CumulativeNonVolatile_RamBlock_Core1, target-data-prototype=CumulativeNonVolatile_Ram_Core1/EeRCVR_U_HT_CabVlvSts_Max}, written-nv-data=EeRCVR_U_HT_CabVlvSts_Max_Rx.EeRCVR_U_HT_CabVlvSts_Max}
        {nv-ram-block-element=autosar-variable-in-impl-datatype={root-variable-data-prototype=CumulativeNonVolatile_RamBlock_Core1, target-data-prototype=CumulativeNonVolatile_Ram_Core1/EeBPSR_U_LrndBrkPdlRestPos}, read-nv-data=EeBPSR_U_LrndBrkPdlRestPos.EeBPSR_U_LrndBrkPdlRestPos}
        {nv-ram-block-element=autosar-variable-in-impl-datatype={root-variable-data-prototype=CumulativeNonVolatile_RamBlock_Core1, target-data-prototype=CumulativeNonVolatile_Ram_Core1/EeBPSR_U_LrndBrkPdlRestPos}, written-nv-data=EeBPSR_U_LrndBrkPdlRestPos_Rx.EeBPSR_U_LrndBrkPdlRestPos}
        {nv-ram-block-element=autosar-variable-in-impl-datatype={root-variable-data-prototype=CumulativeNonVolatile_RamBlock_Core1, target-data-prototype=CumulativeNonVolatile_Ram_Core1/EeRCVR_Cnt_HTCV_Endstophits}, read-nv-data=EeRCVR_Cnt_HTCV_Endstophits.EeRCVR_Cnt_HTCV_Endstophits}
        {nv-ram-block-element=autosar-variable-in-impl-datatype={root-variable-data-prototype=CumulativeNonVolatile_RamBlock_Core1, target-data-prototype=CumulativeNonVolatile_Ram_Core1/EeRCVR_Cnt_HTCV_Endstophits}, written-nv-data=EeRCVR_Cnt_HTCV_Endstophits_Rx.EeRCVR_Cnt_HTCV_Endstophits}
        {nv-ram-block-element=autosar-variable-in-impl-datatype={root-variable-data-prototype=CumulativeNonVolatile_RamBlock_Core1, target-data-prototype=CumulativeNonVolatile_Ram_Core1/EeRCVR_e_HTCV_Calibration_Sts}, read-nv-data=EeRCVR_e_HTCV_Calibration_Sts.EeRCVR_e_HTCV_Calibration_Sts}
        {nv-ram-block-element=autosar-variable-in-impl-datatype={root-variable-data-prototype=CumulativeNonVolatile_RamBlock_Core1, target-data-prototype=CumulativeNonVolatile_Ram_Core1/EeRCVR_e_HTCV_Calibration_Sts}, written-nv-data=EeRCVR_e_HTCV_Calibration_Sts_Rx.EeRCVR_e_HTCV_Calibration_Sts}
        {nv-ram-block-element=autosar-variable-in-impl-datatype={root-variable-data-prototype=CumulativeNonVolatile_RamBlock_Core1, target-data-prototype=CumulativeNonVolatile_Ram_Core1/EeRCVR_Cnt_OEXV_CyclesSncCal}, read-nv-data=EeRCVR_Cnt_OEXV_CyclesSncCal.EeRCVR_Cnt_OEXV_CyclesSncCal}
        {nv-ram-block-element=autosar-variable-in-impl-datatype={root-variable-data-prototype=CumulativeNonVolatile_RamBlock_Core1, target-data-prototype=CumulativeNonVolatile_Ram_Core1/EeRCVR_Cnt_OEXV_CyclesSncCal}, written-nv-data=EeRCVR_Cnt_OEXV_CyclesSncCal_Rx.EeRCVR_Cnt_OEXV_CyclesSncCal}
        {nv-ram-block-element=autosar-variable-in-impl-datatype={root-variable-data-prototype=CumulativeNonVolatile_RamBlock_Core1, target-data-prototype=CumulativeNonVolatile_Ram_Core1/EeRCVR_Cnt_EXV_CyclesSncCal}, read-nv-data=EeRCVR_Cnt_EXV_CyclesSncCal.EeRCVR_Cnt_EXV_CyclesSncCal}
        {nv-ram-block-element=autosar-variable-in-impl-datatype={root-variable-data-prototype=CumulativeNonVolatile_RamBlock_Core1, target-data-prototype=CumulativeNonVolatile_Ram_Core1/EeRCVR_Cnt_EXV_CyclesSncCal}, written-nv-data=EeRCVR_Cnt_EXV_CyclesSncCal_Rx.EeRCVR_Cnt_EXV_CyclesSncCal}
        {nv-ram-block-element=autosar-variable-in-impl-datatype={root-variable-data-prototype=CumulativeNonVolatile_RamBlock_Core1, target-data-prototype=CumulativeNonVolatile_Ram_Core1/EeRCVR_Cnt_EEXV_CyclesSncCal}, read-nv-data=EeRCVR_Cnt_EEXV_CyclesSncCal.EeRCVR_Cnt_EEXV_CyclesSncCal}
        {nv-ram-block-element=autosar-variable-in-impl-datatype={root-variable-data-prototype=CumulativeNonVolatile_RamBlock_Core1, target-data-prototype=CumulativeNonVolatile_Ram_Core1/EeRCVR_Cnt_EEXV_CyclesSncCal}, written-nv-data=EeRCVR_Cnt_EEXV_CyclesSncCal_Rx.EeRCVR_Cnt_EEXV_CyclesSncCal}
        {nv-ram-block-element=autosar-variable-in-impl-datatype={root-variable-data-prototype=CumulativeNonVolatile_RamBlock_Core1, target-data-prototype=CumulativeNonVolatile_Ram_Core1/EeHTRR_Cnt_Htr_Unlck_RstSts}, read-nv-data=EeHTRR_Cnt_Htr_Unlck_RstSts.EeHTRR_Cnt_Htr_Unlck_RstSts}
        {nv-ram-block-element=autosar-variable-in-impl-datatype={root-variable-data-prototype=CumulativeNonVolatile_RamBlock_Core1, target-data-prototype=CumulativeNonVolatile_Ram_Core1/EeHTRR_Cnt_Htr_Unlck_RstSts}, written-nv-data=EeHTRR_Cnt_Htr_Unlck_RstSts_Rx.EeHTRR_Cnt_Htr_Unlck_RstSts}
        {nv-ram-block-element=autosar-variable-in-impl-datatype={root-variable-data-prototype=CumulativeNonVolatile_RamBlock_Core1, target-data-prototype=CumulativeNonVolatile_Ram_Core1/EeFSCR_b_HoodAjar_FanOff}, read-nv-data=EeFSCR_b_HoodAjar_FanOff.EeFSCR_b_HoodAjar_FanOff}
        {nv-ram-block-element=autosar-variable-in-impl-datatype={root-variable-data-prototype=CumulativeNonVolatile_RamBlock_Core1, target-data-prototype=CumulativeNonVolatile_Ram_Core1/EeFSCR_b_HoodAjar_FanOff}, written-nv-data=EeFSCR_b_HoodAjar_FanOff_Rx.EeFSCR_b_HoodAjar_FanOff}
        {nv-ram-block-element=autosar-variable-in-impl-datatype={root-variable-data-prototype=CumulativeNonVolatile_RamBlock_Core1, target-data-prototype=CumulativeNonVolatile_Ram_Core1/EeHTRR_Cnt_Htr_UnlockCntr}, read-nv-data=EeHTRR_Cnt_Htr_UnlockCntr.EeHTRR_Cnt_Htr_UnlockCntr}
        {nv-ram-block-element=autosar-variable-in-impl-datatype={root-variable-data-prototype=CumulativeNonVolatile_RamBlock_Core1, target-data-prototype=CumulativeNonVolatile_Ram_Core1/EeHTRR_Cnt_Htr_UnlockCntr}, written-nv-data=EeHTRR_Cnt_Htr_UnlockCntr_Rx.EeHTRR_Cnt_Htr_UnlockCntr}
      nv block needs NvBlockNeeds: calc-ram-block-crc=false, check-static-block-id=false, readonly=false, resistant-to-changed-sw=true, restore-at-start=true, store-at-shutdown=true, store-cyclic=false, store-emergency=false, store-immediate=false, use-auto-validation-at-shut-down=false, use-crc-comp-mechanism=true, write-only-once=false, write-verification=false
      ram block CumulativeNonVolatile_RamBlock_Core1: type=CumulativeNonVolatile_Ram_Core1, init-value={short-label=CumulativeNonVolatile_Ram_Core1, fields=[EeRCVR_U_HT_CabVlvSts_Min:0, EeRCVR_U_HT_CabVlvSts_Max:0, EeBPSR_U_LrndBrkPdlRestPos:0, EeRCVR_Cnt_HTCV_Endstophits:0, EeRCVR_e_HTCV_Calibration_Sts:255, EeRCVR_Cnt_OEXV_CyclesSncCal:0, EeRCVR_Cnt_EXV_CyclesSncCal:0, EeRCVR_Cnt_EEXV_CyclesSncCal:0, EeHTRR_Cnt_Htr_Unlck_RstSts:0, EeFSCR_b_HoodAjar_FanOff:0, EeHTRR_Cnt_Htr_UnlockCntr:0, Reserved1:0, Reserved2:0, Reserved3:0, Reserved4:0, Reserved5:0, Reserved6:0, Reserved7:0, Reserved8:0, Reserved9:0, Reserved10:0, Reserved11:0, Reserved12:0, Reserved13:0, Reserved14:0, Reserved15:0, Reserved16:0, Reserved17:0, Reserved18:0, Reserved19:0, Reserved20:0, Reserved21:0, Reserved22:0, Reserved23:0, Reserved24:0, Reserved25:0, Reserved26:0]}
      rom block CumulativeNonVolatile_RomBlock_Core1: type=CumulativeNonVolatile_Rom_Core1, init-value={short-label=CumulativeNonVolatile_Rom_Core1, fields=[EeRCVR_U_HT_CabVlvSts_Min:0, EeRCVR_U_HT_CabVlvSts_Max:0, EeBPSR_U_LrndBrkPdlRestPos:0, EeRCVR_Cnt_HTCV_Endstophits:0, EeRCVR_e_HTCV_Calibration_Sts:255, EeRCVR_Cnt_OEXV_CyclesSncCal:0, EeRCVR_Cnt_EXV_CyclesSncCal:0, EeRCVR_Cnt_EEXV_CyclesSncCal:0, EeHTRR_Cnt_Htr_Unlck_RstSts:0, EeFSCR_b_HoodAjar_FanOff:0, EeHTRR_Cnt_Htr_UnlockCntr:0, Reserved1:0, Reserved2:0, Reserved3:0, Reserved4:0, Reserved5:0, Reserved6:0, Reserved7:0, Reserved8:0, Reserved9:0, Reserved10:0, Reserved11:0, Reserved12:0, Reserved13:0, Reserved14:0, Reserved15:0, Reserved16:0, Reserved17:0, Reserved18:0, Reserved19:0, Reserved20:0, Reserved21:0, Reserved22:0, Reserved23:0, Reserved24:0, Reserved25:0, Reserved26:0]}
    nv block descriptor StaticNonVolatile_Descr_Core1: support-dirty-flag=true
      nv-block-data-mappings:
        {nv-ram-block-element=autosar-variable-in-impl-datatype={root-variable-data-prototype=StaticNonVolatile_RamBlock_Core1, target-data-prototype=StaticNonVolatile_Ram_Core1/BeFSCR_b_RadFanTst_NotCmplte}, read-nv-data=BeFSCR_b_RadFanTst_NotCmplte.BeFSCR_b_RadFanTst_NotCmplte}
        {nv-ram-block-element=autosar-variable-in-impl-datatype={root-variable-data-prototype=StaticNonVolatile_RamBlock_Core1, target-data-prototype=StaticNonVolatile_Ram_Core1/BeFSCR_b_RadFanTst_NotCmplte}, written-nv-data=BeFSCR_b_RadFanTst_NotCmplte_Rx.BeFSCR_b_RadFanTst_NotCmplte}
        {nv-ram-block-element=autosar-variable-in-impl-datatype={root-variable-data-prototype=StaticNonVolatile_RamBlock_Core1, target-data-prototype=StaticNonVolatile_Ram_Core1/BeFSCR_b_RadFanTst_Failed}, read-nv-data=BeFSCR_b_RadFanTst_Failed.BeFSCR_b_RadFanTst_Failed}
        {nv-ram-block-element=autosar-variable-in-impl-datatype={root-variable-data-prototype=StaticNonVolatile_RamBlock_Core1, target-data-prototype=StaticNonVolatile_Ram_Core1/BeFSCR_b_RadFanTst_Failed}, written-nv-data=BeFSCR_b_RadFanTst_Failed_Rx.BeFSCR_b_RadFanTst_Failed}
      nv block needs NvBlockNeeds: calc-ram-block-crc=false, check-static-block-id=false, readonly=false, resistant-to-changed-sw=true, restore-at-start=true, store-at-shutdown=true, store-cyclic=false, store-emergency=false, store-immediate=false, use-auto-validation-at-shut-down=false, use-crc-comp-mechanism=true, write-only-once=true, write-verification=false
      ram block StaticNonVolatile_RamBlock_Core1: type=StaticNonVolatile_Ram_Core1, init-value={short-label=StaticNonVolatile_Ram_Core1, fields=[BeFSCR_b_RadFanTst_NotCmplte:1, BeFSCR_b_RadFanTst_Failed:1, Reserved1:0, Reserved2:0, Reserved3:0, Reserved4:0, Reserved5:0, Reserved6:0, Reserved7:0, Reserved8:0, Reserved9:0, Reserved10:0, Reserved11:0, Reserved12:0, Reserved13:0, Reserved14:0, Reserved15:0, Reserved16:0, Reserved17:0, Reserved18:0, Reserved19:0, Reserved20:0, Reserved21:0, Reserved22:0, Reserved23:0, Reserved24:0, Reserved25:0, Reserved26:0]}
      rom block StaticNonVolatile_RomBlock_Core1: type=StaticNonVolatile_Rom_Core1, init-value={short-label=StaticNonVolatile_Rom_Core1, fields=[BeFSCR_b_RadFanTst_NotCmplte:1, BeFSCR_b_RadFanTst_Failed:1, Reserved1:0, Reserved2:0, Reserved3:0, Reserved4:0, Reserved5:0, Reserved6:0, Reserved7:0, Reserved8:0, Reserved9:0, Reserved10:0, Reserved11:0, Reserved12:0, Reserved13:0, Reserved14:0, Reserved15:0, Reserved16:0, Reserved17:0, Reserved18:0, Reserved19:0, Reserved20:0, Reserved21:0, Reserved22:0, Reserved23:0, Reserved24:0, Reserved25:0, Reserved26:0]}
package /IFEepNVBlk_1
  6 x impl type, all with category=STRUCTURE:
    ExpendableNonVolatile_Ram_Core1
      95 x element, all with category=TYPE_REFERENCE:
        NaTCCR_r_A_STRAT_DS_KF: implementation-data-type=rt_Array_Float_22
        NaTCCR_r_A_STRAT_DS: implementation-data-type=rt_Array_Float_22
        NaTCCR_r_B_STRAT_KF_DS: implementation-data-type=rt_Array_Float_22
        NaTCCR_r_B_STRAT_DS: implementation-data-type=rt_Array_Float_22
        NaTCCR_r_A_STRAT_KF_DS: implementation-data-type=rt_Array_Float_22
        NeHCCR_t_C1_FillTimeEst_DS: implementation-data-type=float32
        NeHCCR_p_C2_TchPt_PresEst_DS: implementation-data-type=float32
        NeESSR_M_SpinDwnAddtlOffset: implementation-data-type=float32
        NeESSR_M_SpinUpAddtlOffset: implementation-data-type=float32
        NeESSR_g_StrtStpFailRsn: implementation-data-type=uint32
        NeESSR_g_StrtStpFailRsn2: implementation-data-type=uint32
        NeESSR_k_EngStpProfAngAdpt: implementation-data-type=float32
        NeESSR_k_EngStpProfNiDotGainAdapt: implementation-data-type=float32
        NeHCCR_t_C2_FillTimeEst_DS: implementation-data-type=float32
        NeHCCR_T_C1_Temp_DS: implementation-data-type=float32
        NeHCCR_T_C2_Temp_DS: implementation-data-type=float32
        NeHCCR_l_C1_TchPt_PosnEst_DS: implementation-data-type=float32
        NeHCCR_l_C2_TchPt_PosnEst_DS: implementation-data-type=float32
        NeHCCR_p_C1_TchPt_PresEst_DS: implementation-data-type=float32
        NeWTAR_Pct_GradeCurrent_xSEM4AeCst: implementation-data-type=float32
        NeLLER_r_NvMin_TireTol_Ratio_FL: implementation-data-type=float32
        NeLLER_r_NvMin_TireTol_Ratio_FR: implementation-data-type=float32
        NeLLER_r_NvMin_TireTol_Ratio_RL: implementation-data-type=float32
        NeLLER_r_NvMin_TireTol_Ratio_RR: implementation-data-type=float32
        NePMPR_n_LT_PsvPmpCmd_AD: implementation-data-type=float32
        NePMPR_n_LT_PsvPmp2Cmd_AD: implementation-data-type=float32
        NeSTRR_g_BackupStrtRsn: implementation-data-type=uint32
        NeBPDR_phi_NegSlipIntegrated: implementation-data-type=float32
        NeBPDR_phi_PosSlipIntegrated: implementation-data-type=float32
        NeTHMR_t_PumpStrtTimeT1: implementation-data-type=uint32
        NeTHMR_t_PumpRunTmr: implementation-data-type=uint32
        NeWTAR_Pct_GradeCurrent_xSEM: implementation-data-type=float32
        NeWTAR_Pct_GradeCurrent_Raw: implementation-data-type=float32
        NeWTAR_Pct_GradeCurrent: implementation-data-type=float32
        NeUBTR_t_RealTime_Prev: implementation-data-type=uint32
        NeUBTR_T_UnderhoodTempPred_Prev: implementation-data-type=float32
        NeUBTR_T_BeltTempPred_Prev: implementation-data-type=float32
        NeCSDR_phi_C2SlipIntegrated: implementation-data-type=float32
        NeSTRR_t_RealTime_EngOff: implementation-data-type=uint32
        NeCSDR_phi_C1SlipIntegrated: implementation-data-type=float32
        NeTFTR_t_GenRealTime_Prev: implementation-data-type=uint32
        NeTFTR_T_TransOilTempPred_Prev: implementation-data-type=float32
        NeTFTR_T_GenOilTempEst_Prev: implementation-data-type=float32
        NeTFTR_t_RealTime_Prev: implementation-data-type=uint32
        NeSTRR_g_ImmedStopRsn: implementation-data-type=uint32
        NeSTRR_g_BumpStrtRsn: implementation-data-type=uint32
        NeRCVR_Cnt_LTR_CntrlrShtDwn_Cycles: implementation-data-type=sint16
        NeRCVR_Cnt_HtrCore_CntrlrShtDwn_Cycles: implementation-data-type=sint16
        NeRCVR_Cnt_HTL_CntrlrShtDwn_Cycles: implementation-data-type=sint16
        NeRCVR_Cnt_CPV_CntrlrShtDwn_Cycles: implementation-data-type=sint16
        NeHCCR_Cnt_C2CShifts_TchPtLrn: implementation-data-type=uint16
        NeHCCR_Cnt_AllC2CShifts: implementation-data-type=uint16
        NeESSR_Cnt_AdptInitValue: implementation-data-type=uint16
        NeBPDR_Cnt_BeltSlip_MFOP: implementation-data-type=uint16
        NeBPSD_Cnt_BrkPdlLvlOneCktHi_MFOP: implementation-data-type=uint16
        NeBPSD_Cnt_BrkPdlLvlOneCktLo_MFOP: implementation-data-type=uint16
        NeBPSD_Cnt_BrkPdlSnsPerf_MFOP: implementation-data-type=uint16
        NeTCCR_b_UpdLaw_DS: implementation-data-type=boolean
        NeSTFR_b_FailedStrtPrevCycle: implementation-data-type=boolean
        NeSTRR_b_RealTime_EngOFF_FA: implementation-data-type=boolean
        NeSTRR_b_StrtFailLowPwrLtch: implementation-data-type=boolean
        NePMPR_e_LTPsvPump_PstRnSt: implementation-data-type=TeTMIR_e_ECM_LTP_FanAftRunRq
        NePMPR_e_LTPsvPump2_PstRnSt: implementation-data-type=TeTMIR_e_ECM_LTP_FanAftRunRq
        NePMPR_e_LT_PsvPmp2_PostRunCmd_AD: implementation-data-type=TeTMIR_e_ECM_LTP_FanAftRunRq
        NeTMIR_e_HCP_LTP_FanAftRun_Rq: implementation-data-type=TeTMIR_e_ECM_LTP_FanAftRunRq
        NePMPR_e_LT_PsvPmp_PostRunCmd_AD: implementation-data-type=TeTMIR_e_ECM_LTP_FanAftRunRq
        NeHCCR_b_C2TchPt_DtctFlg_DS: implementation-data-type=boolean
        NeHCCR_b_C1TchPt_DtctFlg_DS: implementation-data-type=boolean
        Reserved{1..27}: implementation-data-type=uint8
    ExpendableNonVolatile_Rom_Core1
      95 x element, all with category=TYPE_REFERENCE:
        NaTCCR_r_A_STRAT_DS_KF: implementation-data-type=rt_Array_Float_22
        NaTCCR_r_A_STRAT_DS: implementation-data-type=rt_Array_Float_22
        NaTCCR_r_B_STRAT_KF_DS: implementation-data-type=rt_Array_Float_22
        NaTCCR_r_B_STRAT_DS: implementation-data-type=rt_Array_Float_22
        NaTCCR_r_A_STRAT_KF_DS: implementation-data-type=rt_Array_Float_22
        NeHCCR_t_C1_FillTimeEst_DS: implementation-data-type=float32
        NeHCCR_p_C2_TchPt_PresEst_DS: implementation-data-type=float32
        NeESSR_M_SpinDwnAddtlOffset: implementation-data-type=float32
        NeESSR_M_SpinUpAddtlOffset: implementation-data-type=float32
        NeESSR_g_StrtStpFailRsn: implementation-data-type=uint32
        NeESSR_g_StrtStpFailRsn2: implementation-data-type=uint32
        NeESSR_k_EngStpProfAngAdpt: implementation-data-type=float32
        NeESSR_k_EngStpProfNiDotGainAdapt: implementation-data-type=float32
        NeHCCR_t_C2_FillTimeEst_DS: implementation-data-type=float32
        NeHCCR_T_C1_Temp_DS: implementation-data-type=float32
        NeHCCR_T_C2_Temp_DS: implementation-data-type=float32
        NeHCCR_l_C1_TchPt_PosnEst_DS: implementation-data-type=float32
        NeHCCR_l_C2_TchPt_PosnEst_DS: implementation-data-type=float32
        NeHCCR_p_C1_TchPt_PresEst_DS: implementation-data-type=float32
        NeWTAR_Pct_GradeCurrent_xSEM4AeCst: implementation-data-type=float32
        NeLLER_r_NvMin_TireTol_Ratio_FL: implementation-data-type=float32
        NeLLER_r_NvMin_TireTol_Ratio_FR: implementation-data-type=float32
        NeLLER_r_NvMin_TireTol_Ratio_RL: implementation-data-type=float32
        NeLLER_r_NvMin_TireTol_Ratio_RR: implementation-data-type=float32
        NePMPR_n_LT_PsvPmpCmd_AD: implementation-data-type=float32
        NePMPR_n_LT_PsvPmp2Cmd_AD: implementation-data-type=float32
        NeSTRR_g_BackupStrtRsn: implementation-data-type=uint32
        NeBPDR_phi_NegSlipIntegrated: implementation-data-type=float32
        NeBPDR_phi_PosSlipIntegrated: implementation-data-type=float32
        NeTHMR_t_PumpStrtTimeT1: implementation-data-type=uint32
        NeTHMR_t_PumpRunTmr: implementation-data-type=uint32
        NeWTAR_Pct_GradeCurrent_xSEM: implementation-data-type=float32
        NeWTAR_Pct_GradeCurrent_Raw: implementation-data-type=float32
        NeWTAR_Pct_GradeCurrent: implementation-data-type=float32
        NeUBTR_t_RealTime_Prev: implementation-data-type=uint32
        NeUBTR_T_UnderhoodTempPred_Prev: implementation-data-type=float32
        NeUBTR_T_BeltTempPred_Prev: implementation-data-type=float32
        NeCSDR_phi_C2SlipIntegrated: implementation-data-type=float32
        NeSTRR_t_RealTime_EngOff: implementation-data-type=uint32
        NeCSDR_phi_C1SlipIntegrated: implementation-data-type=float32
        NeTFTR_t_GenRealTime_Prev: implementation-data-type=uint32
        NeTFTR_T_TransOilTempPred_Prev: implementation-data-type=float32
        NeTFTR_T_GenOilTempEst_Prev: implementation-data-type=float32
        NeTFTR_t_RealTime_Prev: implementation-data-type=uint32
        NeSTRR_g_ImmedStopRsn: implementation-data-type=uint32
        NeSTRR_g_BumpStrtRsn: implementation-data-type=uint32
        NeRCVR_Cnt_LTR_CntrlrShtDwn_Cycles: implementation-data-type=sint16
        NeRCVR_Cnt_HtrCore_CntrlrShtDwn_Cycles: implementation-data-type=sint16
        NeRCVR_Cnt_HTL_CntrlrShtDwn_Cycles: implementation-data-type=sint16
        NeRCVR_Cnt_CPV_CntrlrShtDwn_Cycles: implementation-data-type=sint16
        NeHCCR_Cnt_C2CShifts_TchPtLrn: implementation-data-type=uint16
        NeHCCR_Cnt_AllC2CShifts: implementation-data-type=uint16
        NeESSR_Cnt_AdptInitValue: implementation-data-type=uint16
        NeBPDR_Cnt_BeltSlip_MFOP: implementation-data-type=uint16
        NeBPSD_Cnt_BrkPdlLvlOneCktHi_MFOP: implementation-data-type=uint16
        NeBPSD_Cnt_BrkPdlLvlOneCktLo_MFOP: implementation-data-type=uint16
        NeBPSD_Cnt_BrkPdlSnsPerf_MFOP: implementation-data-type=uint16
        NeTCCR_b_UpdLaw_DS: implementation-data-type=boolean
        NeSTFR_b_FailedStrtPrevCycle: implementation-data-type=boolean
        NeSTRR_b_RealTime_EngOFF_FA: implementation-data-type=boolean
        NeSTRR_b_StrtFailLowPwrLtch: implementation-data-type=boolean
        NePMPR_e_LTPsvPump_PstRnSt: implementation-data-type=TeTMIR_e_ECM_LTP_FanAftRunRq
        NePMPR_e_LTPsvPump2_PstRnSt: implementation-data-type=TeTMIR_e_ECM_LTP_FanAftRunRq
        NePMPR_e_LT_PsvPmp2_PostRunCmd_AD: implementation-data-type=TeTMIR_e_ECM_LTP_FanAftRunRq
        NeTMIR_e_HCP_LTP_FanAftRun_Rq: implementation-data-type=TeTMIR_e_ECM_LTP_FanAftRunRq
        NePMPR_e_LT_PsvPmp_PostRunCmd_AD: implementation-data-type=TeTMIR_e_ECM_LTP_FanAftRunRq
        NeHCCR_b_C2TchPt_DtctFlg_DS: implementation-data-type=boolean
        NeHCCR_b_C1TchPt_DtctFlg_DS: implementation-data-type=boolean
        Reserved{1..27}: implementation-data-type=uint8
    CumulativeNonVolatile_Ram_Core1
      37 x element, all with category=TYPE_REFERENCE:
        EeRCVR_U_HT_CabVlvSts_Min: implementation-data-type=float32
        EeRCVR_U_HT_CabVlvSts_Max: implementation-data-type=float32
        EeBPSR_U_LrndBrkPdlRestPos: implementation-data-type=float32
        EeRCVR_Cnt_HTCV_Endstophits: implementation-data-type=sint16
        EeRCVR_e_HTCV_Calibration_Sts: implementation-data-type=sint16
        EeRCVR_Cnt_OEXV_CyclesSncCal: implementation-data-type=sint16
        EeRCVR_Cnt_EXV_CyclesSncCal: implementation-data-type=sint16
        EeRCVR_Cnt_EEXV_CyclesSncCal: implementation-data-type=sint16
        EeHTRR_Cnt_Htr_Unlck_RstSts: implementation-data-type=sint16
        EeFSCR_b_HoodAjar_FanOff: implementation-data-type=boolean
        EeHTRR_Cnt_Htr_UnlockCntr: implementation-data-type=uint8
        Reserved{1..26}: implementation-data-type=uint8
    CumulativeNonVolatile_Rom_Core1
      37 x element, all with category=TYPE_REFERENCE:
        EeRCVR_U_HT_CabVlvSts_Min: implementation-data-type=float32
        EeRCVR_U_HT_CabVlvSts_Max: implementation-data-type=float32
        EeBPSR_U_LrndBrkPdlRestPos: implementation-data-type=float32
        EeRCVR_Cnt_HTCV_Endstophits: implementation-data-type=sint16
        EeRCVR_e_HTCV_Calibration_Sts: implementation-data-type=sint16
        EeRCVR_Cnt_OEXV_CyclesSncCal: implementation-data-type=sint16
        EeRCVR_Cnt_EXV_CyclesSncCal: implementation-data-type=sint16
        EeRCVR_Cnt_EEXV_CyclesSncCal: implementation-data-type=sint16
        EeHTRR_Cnt_Htr_Unlck_RstSts: implementation-data-type=sint16
        EeFSCR_b_HoodAjar_FanOff: implementation-data-type=boolean
        EeHTRR_Cnt_Htr_UnlockCntr: implementation-data-type=uint8
        Reserved{1..26}: implementation-data-type=uint8
    StaticNonVolatile_Ram_Core1
      28 x element, all with category=TYPE_REFERENCE:
        BeFSCR_b_RadFanTst_NotCmplte: implementation-data-type=boolean
        BeFSCR_b_RadFanTst_Failed: implementation-data-type=boolean
        Reserved{1..26}: implementation-data-type=uint8
    StaticNonVolatile_Rom_Core1
      28 x element, all with category=TYPE_REFERENCE:
        BeFSCR_b_RadFanTst_NotCmplte: implementation-data-type=boolean
        BeFSCR_b_RadFanTst_Failed: implementation-data-type=boolean
        Reserved{1..26}: implementation-data-type=uint8
